VERSION ""

NS_ :

BS_:

BU_: S32V DGPS IPC ADU

BO_ 3221225472 VECTOR__INDEPENDENT_SIG_MSG: 0 Vector__XXX
 SG_ number_of_objects : 0|8@1+ (1,0) [0|64] "" Vector__XXX
 SG_ Obj0_LatitudeDistance : 0|13@1+ (0.01,-40) [-40|41.91] "m" Vector__XXX
 SG_ Obj0_LongitudeDistance : 0|15@1+ (0.01,-100) [-100|227.67] "m" Vector__XXX
 SG_ Obj0_LatitudeSpeed : 0|14@1+ (0.01,-81) [-81|82.83] "m/s" Vector__XXX
 SG_ Obj0_LongitudeSpeed : 0|14@1+ (0.01,-81) [-81|82.83] "m/s" Vector__XXX
 SG_ Obj0_ID : 0|6@1+ (1,0) [1|32] "" Vector__XXX
 SG_ Obj0_Width : 0|10@1+ (0.01,0) [0|10.23] "m" Vector__XXX
 SG_ Obj0_HeadAngle : 0|11@1+ (0.1,-100) [-100|104.7] "deg" Vector__XXX
 SG_ Obj0_type : 0|4@1+ (1,0) [0|15] "m" Vector__XXX
 SG_ Obj0_Length : 0|12@1+ (0.01,0) [0|40.95] "m" Vector__XXX
 SG_ Obj1_LatitudeDistance : 0|13@1+ (0.01,-40) [-40|41.91] "m" Vector__XXX
 SG_ Obj1_LongitudeDistance : 0|15@1+ (0.01,-100) [-100|227.67] "m" Vector__XXX
 SG_ Obj1_LatitudeSpeed : 0|14@1+ (0.01,-81) [-81|82.83] "m/s" Vector__XXX
 SG_ Obj1_LongitudeSpeed : 0|14@1+ (0.01,-81) [-81|82.83] "m/s" Vector__XXX
 SG_ Obj1_ID : 0|6@1+ (1,0) [1|32] "" Vector__XXX
 SG_ Obj1_Width : 0|10@1+ (0.01,0) [0|10.23] "m" Vector__XXX
 SG_ Obj1_HeadAngle : 0|11@1+ (0.1,-100) [-100|104.7] "deg" Vector__XXX
 SG_ Obj1_type : 0|4@1+ (1,0) [0|15] "m" Vector__XXX
 SG_ Obj1_Length : 0|12@1+ (0.01,0) [0|40.95] "m" Vector__XXX
 SG_ Obj2_LatitudeDistance : 0|13@1+ (0.01,-40) [-40|41.91] "m" Vector__XXX
 SG_ Obj2_LongitudeDistance : 0|15@1+ (0.01,-100) [-100|227.67] "m" Vector__XXX
 SG_ Obj2_LatitudeSpeed : 0|14@1+ (0.01,-81) [-81|82.83] "m/s" Vector__XXX
 SG_ Obj2_LongitudeSpeed : 0|14@1+ (0.01,-81) [-81|82.83] "m/s" Vector__XXX
 SG_ Obj2_ID : 0|6@1+ (1,0) [1|32] "" Vector__XXX
 SG_ Obj2_Width : 0|10@1+ (0.01,0) [0|10.23] "m" Vector__XXX
 SG_ Obj2_HeadAngle : 0|11@1+ (0.1,-100) [-100|104.7] "deg" Vector__XXX
 SG_ Obj2_type : 0|4@1+ (1,0) [0|15] "m" Vector__XXX
 SG_ Obj2_Length : 0|12@1+ (0.01,0) [0|40.95] "m" Vector__XXX
 SG_ Obj3_LatitudeDistance : 0|13@1+ (0.01,-40) [-40|41.91] "m" Vector__XXX
 SG_ Obj3_LongitudeDistance : 0|15@1+ (0.01,-100) [-100|227.67] "m" Vector__XXX
 SG_ Obj3_LatitudeSpeed : 0|14@1+ (0.01,-81) [-81|82.83] "m/s" Vector__XXX
 SG_ Obj3_LongitudeSpeed : 0|14@1+ (0.01,-81) [-81|82.83] "m/s" Vector__XXX
 SG_ Obj3_ID : 0|6@1+ (1,0) [1|32] "" Vector__XXX
 SG_ Obj3_Width : 0|10@1+ (0.01,0) [0|10.23] "m" Vector__XXX
 SG_ Obj3_HeadAngle : 0|11@1+ (0.1,-100) [-100|104.7] "deg" Vector__XXX
 SG_ Obj3_type : 0|4@1+ (1,0) [0|15] "m" Vector__XXX
 SG_ Obj3_Length : 0|12@1+ (0.01,0) [0|40.95] "m" Vector__XXX
 SG_ Obj4_LatitudeDistance : 0|13@1+ (0.01,-40) [-40|41.91] "m" Vector__XXX
 SG_ Obj4_LongitudeDistance : 0|15@1+ (0.01,-100) [-100|227.67] "m" Vector__XXX
 SG_ Obj4_LatitudeSpeed : 0|14@1+ (0.01,-81) [-81|82.83] "m/s" Vector__XXX
 SG_ Obj4_LongitudeSpeed : 0|14@1+ (0.01,-81) [-81|82.83] "m/s" Vector__XXX
 SG_ Obj4_ID : 0|6@1+ (1,0) [1|32] "" Vector__XXX
 SG_ Obj4_Width : 0|10@1+ (0.01,0) [0|10.23] "m" Vector__XXX
 SG_ Obj4_HeadAngle : 0|11@1+ (0.1,-100) [-100|104.7] "deg" Vector__XXX
 SG_ Obj4_type : 0|4@1+ (1,0) [0|15] "m" Vector__XXX
 SG_ Obj4_Length : 0|12@1+ (0.01,0) [0|40.95] "m" Vector__XXX
 SG_ Obj5_LatitudeDistance : 0|13@1+ (0.01,-40) [-40|41.91] "m" Vector__XXX
 SG_ Obj5_LongitudeDistance : 0|15@1+ (0.01,-100) [-100|227.67] "m" Vector__XXX
 SG_ Obj5_LatitudeSpeed : 0|14@1+ (0.01,-81) [-81|82.83] "m/s" Vector__XXX
 SG_ Obj5_LongitudeSpeed : 0|14@1+ (0.01,-81) [-81|82.83] "m/s" Vector__XXX
 SG_ Obj5_ID : 0|6@1+ (1,0) [1|32] "" Vector__XXX
 SG_ Obj5_Width : 0|10@1+ (0.01,0) [0|10.23] "m" Vector__XXX
 SG_ Obj5_HeadAngle : 0|11@1+ (0.1,-100) [-100|104.7] "deg" Vector__XXX
 SG_ Obj5_type : 0|4@1+ (1,0) [0|15] "m" Vector__XXX
 SG_ Obj5_Length : 0|12@1+ (0.01,0) [0|40.95] "m" Vector__XXX
 SG_ Obj6_LatitudeDistance : 0|13@1+ (0.01,-40) [-40|41.91] "m" Vector__XXX
 SG_ Obj6_LongitudeDistance : 0|15@1+ (0.01,-100) [-100|227.67] "m" Vector__XXX
 SG_ Obj6_LatitudeSpeed : 0|14@1+ (0.01,-81) [-81|82.83] "m/s" Vector__XXX
 SG_ Obj6_LongitudeSpeed : 0|14@1+ (0.01,-81) [-81|82.83] "m/s" Vector__XXX
 SG_ Obj6_ID : 0|6@1+ (1,0) [1|32] "" Vector__XXX
 SG_ Obj6_Width : 0|10@1+ (0.01,0) [0|10.23] "m" Vector__XXX
 SG_ Obj6_HeadAngle : 0|11@1+ (0.1,-100) [-100|104.7] "deg" Vector__XXX
 SG_ Obj6_type : 0|4@1+ (1,0) [0|15] "m" Vector__XXX
 SG_ Obj6_Length : 0|12@1+ (0.01,0) [0|40.95] "m" Vector__XXX
 SG_ Obj7_LatitudeDistance : 0|13@1+ (0.01,-40) [-40|41.91] "m" Vector__XXX
 SG_ Obj7_LongitudeDistance : 0|15@1+ (0.01,-100) [-100|227.67] "m" Vector__XXX
 SG_ Obj7_LatitudeSpeed : 0|14@1+ (0.01,-81) [-81|82.83] "m/s" Vector__XXX
 SG_ Obj7_LongitudeSpeed : 0|14@1+ (0.01,-81) [-81|82.83] "m/s" Vector__XXX
 SG_ Obj7_ID : 0|6@1+ (1,0) [1|32] "" Vector__XXX
 SG_ Obj7_Width : 0|10@1+ (0.01,0) [0|10.23] "m" Vector__XXX
 SG_ Obj7_HeadAngle : 0|11@1+ (0.1,-100) [-100|104.7] "deg" Vector__XXX
 SG_ Obj7_type : 0|4@1+ (1,0) [0|15] "m" Vector__XXX
 SG_ Obj7_Length : 0|12@1+ (0.01,0) [0|40.95] "m" Vector__XXX
 SG_ Obj8_LatitudeDistance : 0|13@1+ (0.01,-40) [-40|41.91] "m" Vector__XXX
 SG_ Obj8_LongitudeDistance : 0|15@1+ (0.01,-100) [-100|227.67] "m" Vector__XXX
 SG_ Obj8_LatitudeSpeed : 0|14@1+ (0.01,-81) [-81|82.83] "m/s" Vector__XXX
 SG_ Obj8_LongitudeSpeed : 0|14@1+ (0.01,-81) [-81|82.83] "m/s" Vector__XXX
 SG_ Obj8_ID : 0|6@1+ (1,0) [1|32] "" Vector__XXX
 SG_ Obj8_Width : 0|10@1+ (0.01,0) [0|10.23] "m" Vector__XXX
 SG_ Obj8_HeadAngle : 0|11@1+ (0.1,-100) [-100|104.7] "deg" Vector__XXX
 SG_ Obj8_type : 0|4@1+ (1,0) [0|15] "m" Vector__XXX
 SG_ Obj8_Length : 0|12@1+ (0.01,0) [0|40.95] "m" Vector__XXX
 SG_ Obj9_LatitudeDistance : 0|13@1+ (0.01,-40) [-40|41.91] "m" Vector__XXX
 SG_ Obj9_LongitudeDistance : 0|15@1+ (0.01,-100) [-100|227.67] "m" Vector__XXX
 SG_ Obj9_LatitudeSpeed : 0|14@1+ (0.01,-81) [-81|82.83] "m/s" Vector__XXX
 SG_ Obj9_LongitudeSpeed : 0|14@1+ (0.01,-81) [-81|82.83] "m/s" Vector__XXX
 SG_ Obj9_ID : 0|6@1+ (1,0) [1|32] "" Vector__XXX
 SG_ Obj9_Width : 0|10@1+ (0.01,0) [0|10.23] "m" Vector__XXX
 SG_ Obj9_HeadAngle : 0|11@1+ (0.1,-100) [-100|104.7] "deg" Vector__XXX
 SG_ Obj9_type : 0|4@1+ (1,0) [0|15] "m" Vector__XXX
 SG_ Obj9_Length : 0|12@1+ (0.01,0) [0|40.95] "m" Vector__XXX
 SG_ Obj10_LatitudeDistance : 0|13@1+ (0.01,-40) [-40|41.91] "m" Vector__XXX
 SG_ Obj10_LongitudeDistance : 0|15@1+ (0.01,-100) [-100|227.67] "m" Vector__XXX
 SG_ Obj10_LatitudeSpeed : 0|14@1+ (0.01,-81) [-81|82.83] "m/s" Vector__XXX
 SG_ Obj10_LongitudeSpeed : 0|14@1+ (0.01,-81) [-81|82.83] "m/s" Vector__XXX
 SG_ Obj10_ID : 0|6@1+ (1,0) [1|32] "" Vector__XXX
 SG_ Obj10_Width : 0|10@1+ (0.01,0) [0|10.23] "m" Vector__XXX
 SG_ Obj10_HeadAngle : 0|11@1+ (0.1,-100) [-100|104.7] "deg" Vector__XXX
 SG_ Obj10_type : 0|4@1+ (1,0) [0|15] "m" Vector__XXX
 SG_ Obj10_Length : 0|12@1+ (0.01,0) [0|40.95] "m" Vector__XXX
 SG_ Obj11_LatitudeDistance : 0|13@1+ (0.01,-40) [-40|41.91] "m" Vector__XXX
 SG_ Obj11_LongitudeDistance : 0|15@1+ (0.01,-100) [-100|227.67] "m" Vector__XXX
 SG_ Obj11_LatitudeSpeed : 0|14@1+ (0.01,-81) [-81|82.83] "m/s" Vector__XXX
 SG_ Obj11_LongitudeSpeed : 0|14@1+ (0.01,-81) [-81|82.83] "m/s" Vector__XXX
 SG_ Obj11_ID : 0|6@1+ (1,0) [1|32] "" Vector__XXX
 SG_ Obj11_Width : 0|10@1+ (0.01,0) [0|10.23] "m" Vector__XXX
 SG_ Obj11_HeadAngle : 0|11@1+ (0.1,-100) [-100|104.7] "deg" Vector__XXX
 SG_ Obj11_type : 0|4@1+ (1,0) [0|15] "m" Vector__XXX
 SG_ Obj11_Length : 0|12@1+ (0.01,0) [0|40.95] "m" Vector__XXX
 SG_ Obj12_LatitudeDistance : 0|13@1+ (0.01,-40) [-40|41.91] "m" Vector__XXX
 SG_ Obj12_LongitudeDistance : 0|15@1+ (0.01,-100) [-100|227.67] "m" Vector__XXX
 SG_ Obj12_LatitudeSpeed : 0|14@1+ (0.01,-81) [-81|82.83] "m/s" Vector__XXX
 SG_ Obj12_LongitudeSpeed : 0|14@1+ (0.01,-81) [-81|82.83] "m/s" Vector__XXX
 SG_ Obj12_ID : 0|6@1+ (1,0) [1|32] "" Vector__XXX
 SG_ Obj12_Width : 0|10@1+ (0.01,0) [0|10.23] "m" Vector__XXX
 SG_ Obj12_HeadAngle : 0|11@1+ (0.1,-100) [-100|104.7] "deg" Vector__XXX
 SG_ Obj12_type : 0|4@1+ (1,0) [0|15] "m" Vector__XXX
 SG_ Obj12_Length : 0|12@1+ (0.01,0) [0|40.95] "m" Vector__XXX
 SG_ Obj13_LatitudeDistance : 0|13@1+ (0.01,-40) [-40|41.91] "m" Vector__XXX
 SG_ Obj13_LongitudeDistance : 0|15@1+ (0.01,-100) [-100|227.67] "m" Vector__XXX
 SG_ Obj13_LatitudeSpeed : 0|14@1+ (0.01,-81) [-81|82.83] "m/s" Vector__XXX
 SG_ Obj13_LongitudeSpeed : 0|14@1+ (0.01,-81) [-81|82.83] "m/s" Vector__XXX
 SG_ Obj13_ID : 0|6@1+ (1,0) [1|32] "" Vector__XXX
 SG_ Obj13_Width : 0|10@1+ (0.01,0) [0|10.23] "m" Vector__XXX
 SG_ Obj13_HeadAngle : 0|11@1+ (0.1,-100) [-100|104.7] "deg" Vector__XXX
 SG_ Obj13_type : 0|4@1+ (1,0) [0|15] "m" Vector__XXX
 SG_ Obj13_Length : 0|12@1+ (0.01,0) [0|40.95] "m" Vector__XXX
 SG_ Obj14_LatitudeDistance : 0|13@1+ (0.01,-40) [-40|41.91] "m" Vector__XXX
 SG_ Obj14_LongitudeDistance : 0|15@1+ (0.01,-100) [-100|227.67] "m" Vector__XXX
 SG_ Obj14_LatitudeSpeed : 0|14@1+ (0.01,-81) [-81|82.83] "m/s" Vector__XXX
 SG_ Obj14_LongitudeSpeed : 0|14@1+ (0.01,-81) [-81|82.83] "m/s" Vector__XXX
 SG_ Obj14_ID : 0|6@1+ (1,0) [1|32] "" Vector__XXX
 SG_ Obj14_Width : 0|10@1+ (0.01,0) [0|10.23] "m" Vector__XXX
 SG_ Obj14_HeadAngle : 0|11@1+ (0.1,-100) [-100|104.7] "deg" Vector__XXX
 SG_ Obj14_type : 0|4@1+ (1,0) [0|15] "m" Vector__XXX
 SG_ Obj14_Length : 0|12@1+ (0.01,0) [0|40.95] "m" Vector__XXX
 SG_ Obj15_LatitudeDistance : 0|13@1+ (0.01,-40) [-40|41.91] "m" Vector__XXX
 SG_ Obj15_LongitudeDistance : 0|15@1+ (0.01,-100) [-100|227.67] "m" Vector__XXX
 SG_ Obj15_LatitudeSpeed : 0|14@1+ (0.01,-81) [-81|82.83] "m/s" Vector__XXX
 SG_ Obj15_LongitudeSpeed : 0|14@1+ (0.01,-81) [-81|82.83] "m/s" Vector__XXX
 SG_ Obj15_ID : 0|6@1+ (1,0) [1|32] "" Vector__XXX
 SG_ Obj15_Width : 0|10@1+ (0.01,0) [0|10.23] "m" Vector__XXX
 SG_ Obj15_HeadAngle : 0|11@1+ (0.1,-100) [-100|104.7] "deg" Vector__XXX
 SG_ Obj15_type : 0|4@1+ (1,0) [0|15] "m" Vector__XXX
 SG_ Obj15_Length : 0|12@1+ (0.01,0) [0|40.95] "m" Vector__XXX
 SG_ Obj16_LatitudeDistance : 0|13@1+ (0.01,-40) [-40|41.91] "m" Vector__XXX
 SG_ Obj16_LongitudeDistance : 0|15@1+ (0.01,-100) [-100|227.67] "m" Vector__XXX
 SG_ Obj16_LatitudeSpeed : 0|14@1+ (0.01,-81) [-81|82.83] "m/s" Vector__XXX
 SG_ Obj16_LongitudeSpeed : 0|14@1+ (0.01,-81) [-81|82.83] "m/s" Vector__XXX
 SG_ Obj16_ID : 0|6@1+ (1,0) [1|32] "" Vector__XXX
 SG_ Obj16_Width : 0|10@1+ (0.01,0) [0|10.23] "m" Vector__XXX
 SG_ Obj16_HeadAngle : 0|11@1+ (0.1,-100) [-100|104.7] "deg" Vector__XXX
 SG_ Obj16_type : 0|4@1+ (1,0) [0|15] "m" Vector__XXX
 SG_ Obj16_Length : 0|12@1+ (0.01,0) [0|40.95] "m" Vector__XXX
 SG_ Obj17_LatitudeDistance : 0|13@1+ (0.01,-40) [-40|41.91] "m" Vector__XXX
 SG_ Obj17_LongitudeDistance : 0|15@1+ (0.01,-100) [-100|227.67] "m" Vector__XXX
 SG_ Obj17_LatitudeSpeed : 0|14@1+ (0.01,-81) [-81|82.83] "m/s" Vector__XXX
 SG_ Obj17_LongitudeSpeed : 0|14@1+ (0.01,-81) [-81|82.83] "m/s" Vector__XXX
 SG_ Obj17_ID : 0|6@1+ (1,0) [1|32] "" Vector__XXX
 SG_ Obj17_Width : 0|10@1+ (0.01,0) [0|10.23] "m" Vector__XXX
 SG_ Obj17_HeadAngle : 0|11@1+ (0.1,-100) [-100|104.7] "deg" Vector__XXX
 SG_ Obj17_type : 0|4@1+ (1,0) [0|15] "m" Vector__XXX
 SG_ Obj17_Length : 0|12@1+ (0.01,0) [0|40.95] "m" Vector__XXX
 SG_ Obj18_LatitudeDistance : 0|13@1+ (0.01,-40) [-40|41.91] "m" Vector__XXX
 SG_ Obj18_LongitudeDistance : 0|15@1+ (0.01,-100) [-100|227.67] "m" Vector__XXX
 SG_ Obj18_LatitudeSpeed : 0|14@1+ (0.01,-81) [-81|82.83] "m/s" Vector__XXX
 SG_ Obj18_LongitudeSpeed : 0|14@1+ (0.01,-81) [-81|82.83] "m/s" Vector__XXX
 SG_ Obj18_ID : 0|6@1+ (1,0) [1|32] "" Vector__XXX
 SG_ Obj18_Width : 0|10@1+ (0.01,0) [0|10.23] "m" Vector__XXX
 SG_ Obj18_HeadAngle : 0|11@1+ (0.1,-100) [-100|104.7] "deg" Vector__XXX
 SG_ Obj18_type : 0|4@1+ (1,0) [0|15] "m" Vector__XXX
 SG_ Obj18_Length : 0|12@1+ (0.01,0) [0|40.95] "m" Vector__XXX
 SG_ Obj19_LatitudeDistance : 0|13@1+ (0.01,-40) [-40|41.91] "m" Vector__XXX
 SG_ Obj19_LongitudeDistance : 0|15@1+ (0.01,-100) [-100|227.67] "m" Vector__XXX
 SG_ Obj19_LatitudeSpeed : 0|14@1+ (0.01,-81) [-81|82.83] "m/s" Vector__XXX
 SG_ Obj19_LongitudeSpeed : 0|14@1+ (0.01,-81) [-81|82.83] "m/s" Vector__XXX
 SG_ Obj19_ID : 0|6@1+ (1,0) [1|32] "" Vector__XXX
 SG_ Obj19_Width : 0|10@1+ (0.01,0) [0|10.23] "m" Vector__XXX
 SG_ Obj19_HeadAngle : 0|11@1+ (0.1,-100) [-100|104.7] "deg" Vector__XXX
 SG_ Obj19_type : 0|4@1+ (1,0) [0|15] "m" Vector__XXX
 SG_ Obj19_Length : 0|12@1+ (0.01,0) [0|40.95] "m" Vector__XXX
 SG_ Obj20_LatitudeDistance : 0|13@1+ (0.01,-40) [-40|41.91] "m" Vector__XXX
 SG_ Obj20_LongitudeDistance : 0|15@1+ (0.01,-100) [-100|227.67] "m" Vector__XXX
 SG_ Obj20_LatitudeSpeed : 0|14@1+ (0.01,-81) [-81|82.83] "m/s" Vector__XXX
 SG_ Obj20_LongitudeSpeed : 0|14@1+ (0.01,-81) [-81|82.83] "m/s" Vector__XXX
 SG_ Obj20_ID : 0|6@1+ (1,0) [1|32] "" Vector__XXX
 SG_ Obj20_Width : 0|10@1+ (0.01,0) [0|10.23] "m" Vector__XXX
 SG_ Obj20_HeadAngle : 0|11@1+ (0.1,-100) [-100|104.7] "deg" Vector__XXX
 SG_ Obj20_type : 0|4@1+ (1,0) [0|15] "m" Vector__XXX
 SG_ Obj20_Length : 0|12@1+ (0.01,0) [0|40.95] "m" Vector__XXX
 SG_ Obj21_LatitudeDistance : 0|13@1+ (0.01,-40) [-40|41.91] "m" Vector__XXX
 SG_ Obj21_LongitudeDistance : 0|15@1+ (0.01,-100) [-100|227.67] "m" Vector__XXX
 SG_ Obj21_LatitudeSpeed : 0|14@1+ (0.01,-81) [-81|82.83] "m/s" Vector__XXX
 SG_ Obj21_LongitudeSpeed : 0|14@1+ (0.01,-81) [-81|82.83] "m/s" Vector__XXX
 SG_ Obj21_ID : 0|6@1+ (1,0) [1|32] "" Vector__XXX
 SG_ Obj21_Width : 0|10@1+ (0.01,0) [0|10.23] "m" Vector__XXX
 SG_ Obj21_HeadAngle : 0|11@1+ (0.1,-100) [-100|104.7] "deg" Vector__XXX
 SG_ Obj21_type : 0|4@1+ (1,0) [0|15] "m" Vector__XXX
 SG_ Obj21_Length : 0|12@1+ (0.01,0) [0|40.95] "m" Vector__XXX
 SG_ Obj22_LatitudeDistance : 0|13@1+ (0.01,-40) [-40|41.91] "m" Vector__XXX
 SG_ Obj22_LongitudeDistance : 0|15@1+ (0.01,-100) [-100|227.67] "m" Vector__XXX
 SG_ Obj22_LatitudeSpeed : 0|14@1+ (0.01,-81) [-81|82.83] "m/s" Vector__XXX
 SG_ Obj22_LongitudeSpeed : 0|14@1+ (0.01,-81) [-81|82.83] "m/s" Vector__XXX
 SG_ Obj22_ID : 0|6@1+ (1,0) [1|32] "" Vector__XXX
 SG_ Obj22_Width : 0|10@1+ (0.01,0) [0|10.23] "m" Vector__XXX
 SG_ Obj22_HeadAngle : 0|11@1+ (0.1,-100) [-100|104.7] "deg" Vector__XXX
 SG_ Obj22_type : 0|4@1+ (1,0) [0|15] "m" Vector__XXX
 SG_ Obj22_Length : 0|12@1+ (0.01,0) [0|40.95] "m" Vector__XXX
 SG_ Obj23_LatitudeDistance : 0|13@1+ (0.01,-40) [-40|41.91] "m" Vector__XXX
 SG_ Obj23_LongitudeDistance : 0|15@1+ (0.01,-100) [-100|227.67] "m" Vector__XXX
 SG_ Obj23_LatitudeSpeed : 0|14@1+ (0.01,-81) [-81|82.83] "m/s" Vector__XXX
 SG_ Obj23_LongitudeSpeed : 0|14@1+ (0.01,-81) [-81|82.83] "m/s" Vector__XXX
 SG_ Obj23_ID : 0|6@1+ (1,0) [1|32] "" Vector__XXX
 SG_ Obj23_Width : 0|10@1+ (0.01,0) [0|10.23] "m" Vector__XXX
 SG_ Obj23_HeadAngle : 0|11@1+ (0.1,-100) [-100|104.7] "deg" Vector__XXX
 SG_ Obj23_type : 0|4@1+ (1,0) [0|15] "m" Vector__XXX
 SG_ Obj23_Length : 0|12@1+ (0.01,0) [0|40.95] "m" Vector__XXX
 SG_ Obj24_LatitudeDistance : 0|13@1+ (0.01,-40) [-40|41.91] "m" Vector__XXX
 SG_ Obj24_LongitudeDistance : 0|15@1+ (0.01,-100) [-100|227.67] "m" Vector__XXX
 SG_ Obj24_LatitudeSpeed : 0|14@1+ (0.01,-81) [-81|82.83] "m/s" Vector__XXX
 SG_ Obj24_LongitudeSpeed : 0|14@1+ (0.01,-81) [-81|82.83] "m/s" Vector__XXX
 SG_ Obj24_ID : 0|6@1+ (1,0) [1|32] "" Vector__XXX
 SG_ Obj24_Width : 0|10@1+ (0.01,0) [0|10.23] "m" Vector__XXX
 SG_ Obj24_HeadAngle : 0|11@1+ (0.1,-100) [-100|104.7] "deg" Vector__XXX
 SG_ Obj24_type : 0|4@1+ (1,0) [0|15] "m" Vector__XXX
 SG_ Obj24_Length : 0|12@1+ (0.01,0) [0|40.95] "m" Vector__XXX
 SG_ Obj25_LatitudeDistance : 0|13@1+ (0.01,-40) [-40|41.91] "m" Vector__XXX
 SG_ Obj25_LongitudeDistance : 0|15@1+ (0.01,-100) [-100|227.67] "m" Vector__XXX
 SG_ Obj25_LatitudeSpeed : 0|14@1+ (0.01,-81) [-81|82.83] "m/s" Vector__XXX
 SG_ Obj25_LongitudeSpeed : 0|14@1+ (0.01,-81) [-81|82.83] "m/s" Vector__XXX
 SG_ Obj25_ID : 0|6@1+ (1,0) [1|32] "" Vector__XXX
 SG_ Obj25_Width : 0|10@1+ (0.01,0) [0|10.23] "m" Vector__XXX
 SG_ Obj25_HeadAngle : 0|11@1+ (0.1,-100) [-100|104.7] "deg" Vector__XXX
 SG_ Obj25_type : 0|4@1+ (1,0) [0|15] "m" Vector__XXX
 SG_ Obj25_Length : 0|12@1+ (0.01,0) [0|40.95] "m" Vector__XXX
 SG_ Obj26_LatitudeDistance : 0|13@1+ (0.01,-40) [-40|41.91] "m" Vector__XXX
 SG_ Obj26_LongitudeDistance : 0|15@1+ (0.01,-100) [-100|227.67] "m" Vector__XXX
 SG_ Obj26_LatitudeSpeed : 0|14@1+ (0.01,-81) [-81|82.83] "m/s" Vector__XXX
 SG_ Obj26_LongitudeSpeed : 0|14@1+ (0.01,-81) [-81|82.83] "m/s" Vector__XXX
 SG_ Obj26_ID : 0|6@1+ (1,0) [1|32] "" Vector__XXX
 SG_ Obj26_Width : 0|10@1+ (0.01,0) [0|10.23] "m" Vector__XXX
 SG_ Obj26_HeadAngle : 0|11@1+ (0.1,-100) [-100|104.7] "deg" Vector__XXX
 SG_ Obj26_type : 0|4@1+ (1,0) [0|15] "m" Vector__XXX
 SG_ Obj26_Length : 0|12@1+ (0.01,0) [0|40.95] "m" Vector__XXX
 SG_ Obj27_LatitudeDistance : 0|13@1+ (0.01,-40) [-40|41.91] "m" Vector__XXX
 SG_ Obj27_LongitudeDistance : 0|15@1+ (0.01,-100) [-100|227.67] "m" Vector__XXX
 SG_ Obj27_LatitudeSpeed : 0|14@1+ (0.01,-81) [-81|82.83] "m/s" Vector__XXX
 SG_ Obj27_LongitudeSpeed : 0|14@1+ (0.01,-81) [-81|82.83] "m/s" Vector__XXX
 SG_ Obj27_ID : 0|6@1+ (1,0) [1|32] "" Vector__XXX
 SG_ Obj27_Width : 0|10@1+ (0.01,0) [0|10.23] "m" Vector__XXX
 SG_ Obj27_HeadAngle : 0|11@1+ (0.1,-100) [-100|104.7] "deg" Vector__XXX
 SG_ Obj27_type : 0|4@1+ (1,0) [0|15] "m" Vector__XXX
 SG_ Obj27_Length : 0|12@1+ (0.01,0) [0|40.95] "m" Vector__XXX
 SG_ Obj28_LatitudeDistance : 0|13@1+ (0.01,-40) [-40|41.91] "m" Vector__XXX
 SG_ Obj28_LongitudeDistance : 0|15@1+ (0.01,-100) [-100|227.67] "m" Vector__XXX
 SG_ Obj28_LatitudeSpeed : 0|14@1+ (0.01,-81) [-81|82.83] "m/s" Vector__XXX
 SG_ Obj28_LongitudeSpeed : 0|14@1+ (0.01,-81) [-81|82.83] "m/s" Vector__XXX
 SG_ Obj28_ID : 0|6@1+ (1,0) [1|32] "" Vector__XXX
 SG_ Obj28_Width : 0|10@1+ (0.01,0) [0|10.23] "m" Vector__XXX
 SG_ Obj28_HeadAngle : 0|11@1+ (0.1,-100) [-100|104.7] "deg" Vector__XXX
 SG_ Obj28_type : 0|4@1+ (1,0) [0|15] "m" Vector__XXX
 SG_ Obj28_Length : 0|12@1+ (0.01,0) [0|40.95] "m" Vector__XXX
 SG_ Obj29_LatitudeDistance : 0|13@1+ (0.01,-40) [-40|41.91] "m" Vector__XXX
 SG_ Obj29_LongitudeDistance : 0|15@1+ (0.01,-100) [-100|227.67] "m" Vector__XXX
 SG_ Obj29_LatitudeSpeed : 0|14@1+ (0.01,-81) [-81|82.83] "m/s" Vector__XXX
 SG_ Obj29_LongitudeSpeed : 0|14@1+ (0.01,-81) [-81|82.83] "m/s" Vector__XXX
 SG_ Obj29_ID : 0|6@1+ (1,0) [1|32] "" Vector__XXX
 SG_ Obj29_Width : 0|10@1+ (0.01,0) [0|10.23] "m" Vector__XXX
 SG_ Obj29_HeadAngle : 0|11@1+ (0.1,-100) [-100|104.7] "deg" Vector__XXX
 SG_ Obj29_type : 0|4@1+ (1,0) [0|15] "m" Vector__XXX
 SG_ Obj29_Length : 0|12@1+ (0.01,0) [0|40.95] "m" Vector__XXX
 SG_ Obj30_LatitudeDistance : 0|13@1+ (0.01,-40) [-40|41.91] "m" Vector__XXX
 SG_ Obj30_LongitudeDistance : 0|15@1+ (0.01,-100) [-100|227.67] "m" Vector__XXX
 SG_ Obj30_LatitudeSpeed : 0|14@1+ (0.01,-81) [-81|82.83] "m/s" Vector__XXX
 SG_ Obj30_LongitudeSpeed : 0|14@1+ (0.01,-81) [-81|82.83] "m/s" Vector__XXX
 SG_ Obj30_ID : 0|6@1+ (1,0) [1|32] "" Vector__XXX
 SG_ Obj30_Width : 0|10@1+ (0.01,0) [0|10.23] "m" Vector__XXX
 SG_ Obj30_HeadAngle : 0|11@1+ (0.1,-100) [-100|104.7] "deg" Vector__XXX
 SG_ Obj30_type : 0|4@1+ (1,0) [0|15] "m" Vector__XXX
 SG_ Obj30_Length : 0|12@1+ (0.01,0) [0|40.95] "m" Vector__XXX
 SG_ Obj31_LatitudeDistance : 0|13@1+ (0.01,-40) [-40|41.91] "m" Vector__XXX
 SG_ Obj31_LongitudeDistance : 0|15@1+ (0.01,-100) [-100|227.67] "m" Vector__XXX
 SG_ Obj31_LatitudeSpeed : 0|14@1+ (0.01,-81) [-81|82.83] "m/s" Vector__XXX
 SG_ Obj31_LongitudeSpeed : 0|14@1+ (0.01,-81) [-81|82.83] "m/s" Vector__XXX
 SG_ Obj31_ID : 0|6@1+ (1,0) [1|32] "" Vector__XXX
 SG_ Obj31_Width : 0|10@1+ (0.01,0) [0|10.23] "m" Vector__XXX
 SG_ Obj31_HeadAngle : 0|11@1+ (0.1,-100) [-100|104.7] "deg" Vector__XXX
 SG_ Obj31_type : 0|4@1+ (1,0) [0|15] "m" Vector__XXX
 SG_ Obj31_Length : 0|12@1+ (0.01,0) [0|40.95] "m" Vector__XXX
 SG_ GPS_PDOP : 0|16@0+ (0.001,0) [0|65.535] "" Vector__XXX
 SG_ GPS_HDOP : 0|16@0+ (0.001,0) [0|65.535] "" Vector__XXX
 SG_ GPS_VDOP : 0|16@0+ (0.001,0) [0|65.535] "" Vector__XXX
 SG_ GPS_GDOP : 0|16@0+ (0.001,0) [0|65.535] "" Vector__XXX
 SG_ GPS_HeadingAngle : 0|32@0+ (1E-007,-180) [-180|180] "deg" Vector__XXX
 SG_ GPS_LocatHeight : 0|32@0+ (0.001,-10000) [-10000|4284967.295] "m" Vector__XXX
 SG_ GPS_Time : 0|32@0+ (1,0) [0|4294967295] "ms" Vector__XXX
 SG_ GPS_Latitude : 0|32@0+ (1E-007,-180) [-180|180] "deg" Vector__XXX
 SG_ GPS_Lontitude : 0|32@0+ (1E-007,-90) [-90|339.4967295] "deg" Vector__XXX
 SG_ GPS_UTC_sec : 0|32@0+ (1,0) [0|4294967295] "" Vector__XXX
 SG_ GPS_UTC_week : 0|16@0+ (1,0) [0|65500] "" Vector__XXX
 SG_ INS_A_Y : 0|16@0+ (0.00012207,-4) [-4|3.99985745] "m/s^2" Vector__XXX
 SG_ INS_A_X : 0|16@0+ (0.00012207,-4) [-4|3.99985745] "m/s^2" Vector__XXX
 SG_ INS_A_Z : 0|16@0+ (0.00012207,-4) [-4|3.99985745] "m/s^2" Vector__XXX
 SG_ GPS_flag_pos : 0|8@0+ (1,0) [0|60] "" Vector__XXX
 SG_ GPS_flag_heading : 0|8@0+ (1,0) [0|255] "" Vector__XXX
 SG_ GPS_age : 0|8@0+ (1,0) [0|100] "" Vector__XXX
 SG_ car_statue : 0|8@0+ (1,0) [0|12] "" Vector__XXX
 SG_ INS_statue : 0|8@0+ (1,0) [0|255] "" Vector__XXX
 SG_ GPS_numsv : 0|8@0+ (1,0) [0|255] "" Vector__XXX
 SG_ INS_GYRO_Y : 0|16@0+ (0.0076293,-250) [-250|249.9861755] "deg/s" Vector__XXX
 SG_ INS_GYRO_Z : 0|16@0+ (0.0076293,-250) [-250|249.9861755] "deg/s" Vector__XXX
 SG_ INS_GYRO_X : 0|16@0+ (0.0076293,-250) [-250|249.9861755] "deg/s" Vector__XXX
 SG_ INS_RollAngle : 0|16@0+ (0.010986,-360) [-360|359.96751] "deg" Vector__XXX
 SG_ INS_HeadingAngle : 0|16@0+ (0.010986,-360) [-360|359.96751] "deg" Vector__XXX
 SG_ INS_PitchAngle : 0|16@0+ (0.010986,-360) [-360|359.96751] "deg" Vector__XXX
 SG_ INS_LocatHeight : 0|32@0+ (0.001,-10000) [-10000|4284967.295] "m" Vector__XXX
 SG_ INS_Time : 0|32@0+ (1,0) [0|4294967295] "ms" Vector__XXX
 SG_ INS_Latitude : 0|32@0+ (1E-007,-180) [-180|180] "deg" Vector__XXX
 SG_ INS_Longitude : 0|32@0+ (1E-007,-180) [-180|180] "deg" Vector__XXX
 SG_ INS_NorthSpd : 0|16@0+ (0.0030517,-100) [-100|99.9901078] "m/s" Vector__XXX
 SG_ INS_ToGroundSpd : 0|16@0+ (0.0030517,-100) [-100|99.9901078] "m/s" Vector__XXX
 SG_ INS_EastSpd : 0|16@0+ (0.0030517,-100) [-100|99.9901078] "m/s" Vector__XXX
 SG_ INS_Std_Lon : 0|16@0+ (0.001,0) [0|65.535] "m" Vector__XXX
 SG_ INS_Std_Height : 0|16@0+ (0.001,0) [0|65.535] "m" Vector__XXX
 SG_ INS_Std_Lat : 0|16@0+ (0.001,0) [0|65.535] "m" Vector__XXX
 SG_ IPC_CPSLaneNumber : 0|4@1+ (1,0) [0|15] "" Vector__XXX
 SG_ IPC_CPSDirectionIndication : 0|2@1+ (1,0) [0|3] "" Vector__XXX
 SG_ IPC_CPSCameraUsed : 0|2@1+ (1,0) [0|3] "" Vector__XXX
 SG_ IPC_BayNumberCameraUsed : 0|2@1+ (1,0) [0|3] "" Vector__XXX
 SG_ IPC_BayNumber : 0|8@1+ (1,0) [0|99] "" Vector__XXX
 SG_ IPC_BayRemainingDistanceX : 0|16@1+ (1,-3000) [-3000|3000] "" Vector__XXX
 SG_ IPC_BayRemainingDistanceY : 0|16@1+ (1,-3000) [-3000|3000] "" Vector__XXX
 SG_ IPC_CPSDisplayNumber : 0|8@1+ (1,0) [0|99] "cm" Vector__XXX
 SG_ IPC_ContainerSizeAndPosition : 0|4@1+ (1,0) [0|15] "" Vector__XXX
 SG_ IPC_CPSRightCameraStatus : 0|5@1+ (1,0) [0|31] "" Vector__XXX
 SG_ IPC_BayNumLeftCameraStatus : 0|5@1+ (1,0) [0|31] "" Vector__XXX
 SG_ IPC_BayNumRightCameraStatus : 0|5@1+ (1,0) [0|31] "" Vector__XXX
 SG_ IPC_HangerCameraStatus : 0|5@1+ (1,0) [0|31] "" Vector__XXX
 SG_ IPC_HangerStatus : 0|4@1+ (1,0) [0|15] "" Vector__XXX
 SG_ IPC_CPSLeftCameraStatus : 0|5@1+ (1,0) [0|31] "" Vector__XXX
 SG_ S32V_ToADU_Reserved1 : 0|16@1+ (1,0) [0|65535] "" Vector__XXX
 SG_ S32V_ToADU_Reserved2 : 0|16@1+ (1,0) [0|65535] "" Vector__XXX
 SG_ S32V_ToADU_Reserved3 : 0|16@1+ (1,0) [0|65535] "" Vector__XXX
 SG_ S32V_ToADU_Reserved4 : 0|16@1+ (1,0) [0|65535] "" Vector__XXX
 SG_ S32V_ToADU_Reserved5 : 0|16@1+ (1,0) [0|65535] "" Vector__XXX
 SG_ S32V_ToADU_Reserved6 : 0|16@1+ (1,0) [0|65535] "" Vector__XXX
 SG_ S32V_ToADU_Reserved7 : 0|16@1+ (1,0) [0|65535] "" Vector__XXX
 SG_ S32V_ToADU_Reserved8 : 0|16@1+ (1,0) [0|65535] "" Vector__XXX
 SG_ S32V_ToADU_Reserved9 : 0|16@1+ (1,0) [0|65535] "" Vector__XXX
 SG_ S32V_ToADU_Reserved10 : 0|16@1+ (1,0) [0|65535] "" Vector__XXX
 SG_ S32V_ToADU_Reserved11 : 0|16@1+ (1,0) [0|65535] "" Vector__XXX
 SG_ S32V_ToADU_Reserved12 : 0|16@1+ (1,0) [0|65535] "" Vector__XXX
 SG_ S32V_ToADU_Reserved13 : 0|8@1+ (1,0) [0|255] "" Vector__XXX
 SG_ S32V_ToADU_Reserved15 : 0|8@1+ (1,0) [0|255] "" Vector__XXX
 SG_ S32V_ToADU_Reserved16 : 0|8@1+ (1,0) [0|255] "" Vector__XXX
 SG_ S32V_ToADU_Reserved17 : 0|8@1+ (1,0) [0|255] "" Vector__XXX
 SG_ S32V_ToADU_Reserved18 : 0|8@1+ (1,0) [0|255] "" Vector__XXX
 SG_ S32V_ToADU_Reserved19 : 0|8@1+ (1,0) [0|255] "" Vector__XXX
 SG_ S32V_ToADU_Reserved20 : 0|8@1+ (1,0) [0|255] "" Vector__XXX
 SG_ S32V_ToADU_Reserved14 : 0|8@1+ (1,0) [0|255] "" Vector__XXX
 SG_ S32V_ToADU_Reserved21 : 0|8@1+ (1,0) [0|255] "" Vector__XXX
 SG_ S32V_ToADU_Reserved23 : 0|8@1+ (1,0) [0|255] "" Vector__XXX
 SG_ S32V_ToADU_Reserved24 : 0|8@1+ (1,0) [0|255] "" Vector__XXX
 SG_ S32V_ToADU_Reserved25 : 0|8@1+ (1,0) [0|255] "" Vector__XXX
 SG_ S32V_ToADU_Reserved26 : 0|8@1+ (1,0) [0|255] "" Vector__XXX
 SG_ S32V_ToADU_Reserved27 : 0|8@1+ (1,0) [0|255] "" Vector__XXX
 SG_ S32V_ToADU_Reserved28 : 0|8@1+ (1,0) [0|255] "" Vector__XXX
 SG_ S32V_ToADU_Reserved22 : 0|8@1+ (1,0) [0|255] "" Vector__XXX
 SG_ adu_ToS32V_Reserved1 : 0|16@1+ (1,0) [0|65535] "" Vector__XXX
 SG_ adu_ToS32V_Reserved2 : 0|16@1+ (1,0) [0|65535] "" Vector__XXX
 SG_ adu_ToS32V_Reserved3 : 0|16@1+ (1,0) [0|65535] "" Vector__XXX
 SG_ adu_ToS32V_Reserved4 : 0|16@1+ (1,0) [0|65535] "" Vector__XXX
 SG_ adu_ToS32V_Reserved5 : 0|16@1+ (1,0) [0|65535] "" Vector__XXX
 SG_ adu_ToS32V_Reserved6 : 0|16@1+ (1,0) [0|65535] "" Vector__XXX
 SG_ adu_ToS32V_Reserved7 : 0|16@1+ (1,0) [0|65535] "" Vector__XXX
 SG_ adu_ToS32V_Reserved8 : 0|16@1+ (1,0) [0|65535] "" Vector__XXX
 SG_ adu_ToS32V_Reserved9 : 0|16@1+ (1,0) [0|65535] "" Vector__XXX
 SG_ adu_ToS32V_Reserved10 : 0|16@1+ (1,0) [0|65535] "" Vector__XXX
 SG_ adu_ToS32V_Reserved11 : 0|16@1+ (1,0) [0|65535] "" Vector__XXX
 SG_ adu_ToS32V_Reserved12 : 0|16@1+ (1,0) [0|65535] "" Vector__XXX
 SG_ adu_ToS32V_Reserved13 : 0|8@1+ (1,0) [0|255] "" Vector__XXX
 SG_ adu_ToS32V_Reserved15 : 0|8@1+ (1,0) [0|255] "" Vector__XXX
 SG_ adu_ToS32V_Reserved16 : 0|8@1+ (1,0) [0|255] "" Vector__XXX
 SG_ adu_ToS32V_Reserved17 : 0|8@1+ (1,0) [0|255] "" Vector__XXX
 SG_ adu_ToS32V_Reserved18 : 0|8@1+ (1,0) [0|255] "" Vector__XXX
 SG_ adu_ToS32V_Reserved19 : 0|8@1+ (1,0) [0|255] "" Vector__XXX
 SG_ adu_ToS32V_Reserved20 : 0|8@1+ (1,0) [0|255] "" Vector__XXX
 SG_ adu_ToS32V_Reserved14 : 0|8@1+ (1,0) [0|255] "" Vector__XXX
 SG_ adu_ToS32V_Reserved21 : 0|8@1+ (1,0) [0|255] "" Vector__XXX
 SG_ adu_ToS32V_Reserved23 : 0|8@1+ (1,0) [0|255] "" Vector__XXX
 SG_ adu_ToS32V_Reserved24 : 0|8@1+ (1,0) [0|255] "" Vector__XXX
 SG_ adu_ToS32V_Reserved25 : 0|8@1+ (1,0) [0|255] "" Vector__XXX
 SG_ adu_ToS32V_Reserved26 : 0|8@1+ (1,0) [0|255] "" Vector__XXX
 SG_ adu_ToS32V_Reserved27 : 0|8@1+ (1,0) [0|255] "" Vector__XXX
 SG_ adu_ToS32V_Reserved28 : 0|8@1+ (1,0) [0|255] "" Vector__XXX
 SG_ adu_ToS32V_Reserved22 : 0|8@1+ (1,0) [0|255] "" Vector__XXX

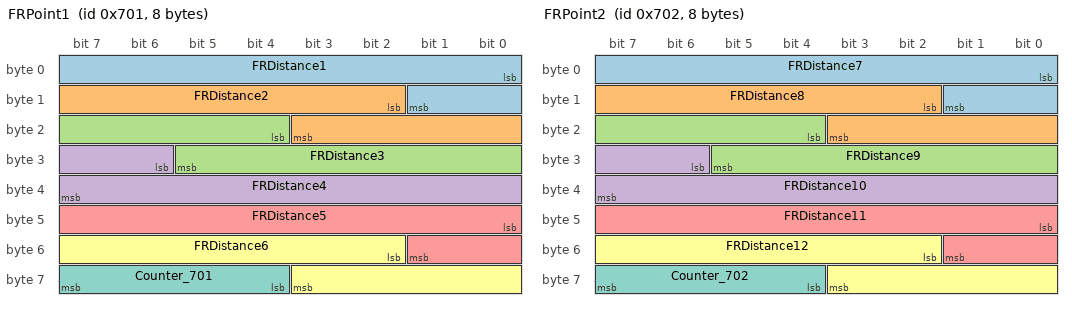
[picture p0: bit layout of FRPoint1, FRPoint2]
BO_ 1793 FRPoint1: 8 S32V
 SG_ FRDistance1 : 0|10@1+ (0.1,0) [0|102.3] "m"  ADU
 SG_ FRDistance2 : 10|10@1+ (0.1,0) [0|102.3] "m"  ADU
 SG_ FRDistance3 : 20|10@1+ (0.1,0) [0|102.3] "m"  ADU
 SG_ FRDistance4 : 30|10@1+ (0.1,0) [0|102.3] "m"  ADU
 SG_ FRDistance5 : 40|10@1+ (0.1,0) [0|102.3] "m"  ADU
 SG_ FRDistance6 : 50|10@1+ (0.1,0) [0|102.3] "m"  ADU
 SG_ Counter_701 : 60|4@1+ (1,0) [0|15] ""  ADU

BO_ 1794 FRPoint2: 8 S32V
 SG_ FRDistance7 : 0|10@1+ (0.1,0) [0|102.3] "m"  ADU
 SG_ FRDistance8 : 10|10@1+ (0.1,0) [0|102.3] "m"  ADU
 SG_ FRDistance9 : 20|10@1+ (0.1,0) [0|102.3] "m"  ADU
 SG_ FRDistance10 : 30|10@1+ (0.1,0) [0|102.3] "m"  ADU
 SG_ FRDistance11 : 40|10@1+ (0.1,0) [0|102.3] "m"  ADU
 SG_ FRDistance12 : 50|10@1+ (0.1,0) [0|102.3] "m"  ADU
 SG_ Counter_702 : 60|4@1+ (1,0) [0|15] ""  ADU

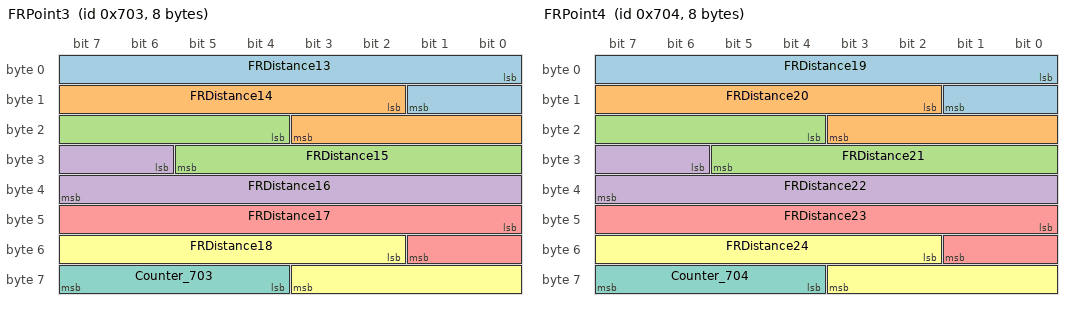
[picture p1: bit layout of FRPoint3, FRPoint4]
BO_ 1795 FRPoint3: 8 S32V
 SG_ FRDistance13 : 0|10@1+ (0.1,0) [0|102.3] "m"  ADU
 SG_ FRDistance14 : 10|10@1+ (0.1,0) [0|102.3] "m"  ADU
 SG_ FRDistance15 : 20|10@1+ (0.1,0) [0|102.3] "m"  ADU
 SG_ FRDistance16 : 30|10@1+ (0.1,0) [0|102.3] "m"  ADU
 SG_ FRDistance17 : 40|10@1+ (0.1,0) [0|102.3] "m"  ADU
 SG_ FRDistance18 : 50|10@1+ (0.1,0) [0|102.3] "m"  ADU
 SG_ Counter_703 : 60|4@1+ (1,0) [0|15] ""  ADU

BO_ 1796 FRPoint4: 8 S32V
 SG_ FRDistance19 : 0|10@1+ (0.1,0) [0|102.3] "m"  ADU
 SG_ FRDistance20 : 10|10@1+ (0.1,0) [0|102.3] "m"  ADU
 SG_ FRDistance21 : 20|10@1+ (0.1,0) [0|102.3] "m"  ADU
 SG_ FRDistance22 : 30|10@1+ (0.1,0) [0|102.3] "m"  ADU
 SG_ FRDistance23 : 40|10@1+ (0.1,0) [0|102.3] "m"  ADU
 SG_ FRDistance24 : 50|10@1+ (0.1,0) [0|102.3] "m"  ADU
 SG_ Counter_704 : 60|4@1+ (1,0) [0|15] ""  ADU

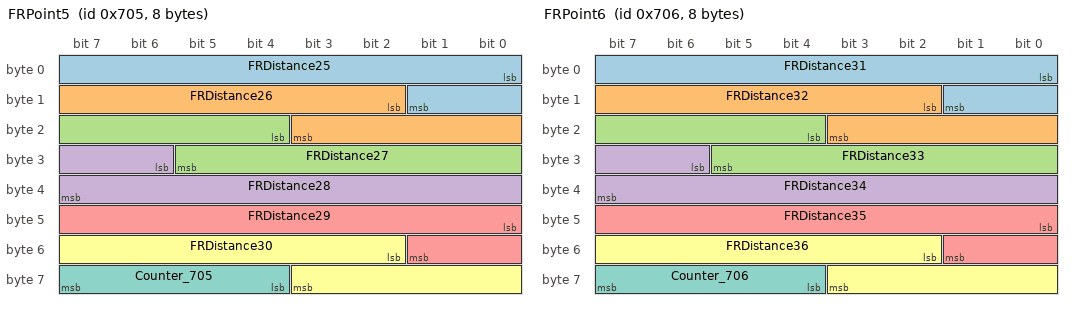
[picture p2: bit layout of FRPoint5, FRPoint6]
BO_ 1797 FRPoint5: 8 S32V
 SG_ FRDistance25 : 0|10@1+ (0.1,0) [0|102.3] "m"  ADU
 SG_ FRDistance26 : 10|10@1+ (0.1,0) [0|102.3] "m"  ADU
 SG_ FRDistance27 : 20|10@1+ (0.1,0) [0|102.3] "m"  ADU
 SG_ FRDistance28 : 30|10@1+ (0.1,0) [0|102.3] "m"  ADU
 SG_ FRDistance29 : 40|10@1+ (0.1,0) [0|102.3] "m"  ADU
 SG_ FRDistance30 : 50|10@1+ (0.1,0) [0|102.3] "m"  ADU
 SG_ Counter_705 : 60|4@1+ (1,0) [0|15] ""  ADU

BO_ 1798 FRPoint6: 8 S32V
 SG_ FRDistance31 : 0|10@1+ (0.1,0) [0|102.3] "m"  ADU
 SG_ FRDistance32 : 10|10@1+ (0.1,0) [0|102.3] "m"  ADU
 SG_ FRDistance33 : 20|10@1+ (0.1,0) [0|102.3] "m"  ADU
 SG_ FRDistance34 : 30|10@1+ (0.1,0) [0|102.3] "m"  ADU
 SG_ FRDistance35 : 40|10@1+ (0.1,0) [0|102.3] "m"  ADU
 SG_ FRDistance36 : 50|10@1+ (0.1,0) [0|102.3] "m"  ADU
 SG_ Counter_706 : 60|4@1+ (1,0) [0|15] ""  ADU

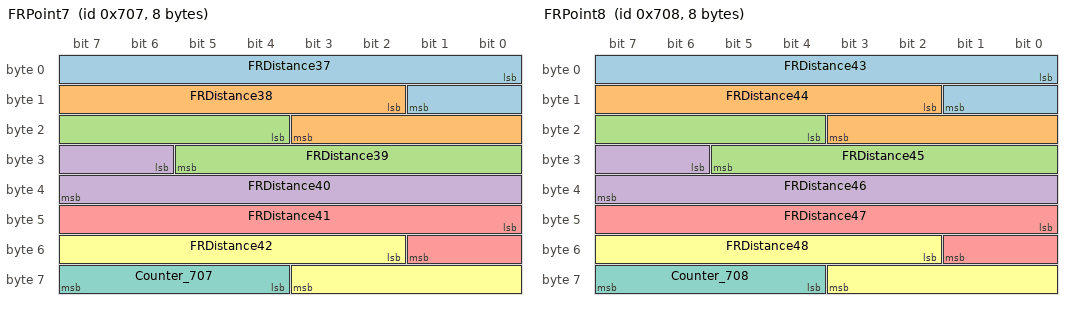
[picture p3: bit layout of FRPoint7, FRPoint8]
BO_ 1799 FRPoint7: 8 S32V
 SG_ FRDistance37 : 0|10@1+ (0.1,0) [0|102.3] "m"  ADU
 SG_ FRDistance38 : 10|10@1+ (0.1,0) [0|102.3] "m"  ADU
 SG_ FRDistance39 : 20|10@1+ (0.1,0) [0|102.3] "m"  ADU
 SG_ FRDistance40 : 30|10@1+ (0.1,0) [0|102.3] "m"  ADU
 SG_ FRDistance41 : 40|10@1+ (0.1,0) [0|102.3] "m"  ADU
 SG_ FRDistance42 : 50|10@1+ (0.1,0) [0|102.3] "m"  ADU
 SG_ Counter_707 : 60|4@1+ (1,0) [0|15] ""  ADU

BO_ 1800 FRPoint8: 8 S32V
 SG_ FRDistance43 : 0|10@1+ (0.1,0) [0|102.3] "m"  ADU
 SG_ FRDistance44 : 10|10@1+ (0.1,0) [0|102.3] "m"  ADU
 SG_ FRDistance45 : 20|10@1+ (0.1,0) [0|102.3] "m"  ADU
 SG_ FRDistance46 : 30|10@1+ (0.1,0) [0|102.3] "m"  ADU
 SG_ FRDistance47 : 40|10@1+ (0.1,0) [0|102.3] "m"  ADU
 SG_ FRDistance48 : 50|10@1+ (0.1,0) [0|102.3] "m"  ADU
 SG_ Counter_708 : 60|4@1+ (1,0) [0|15] ""  ADU

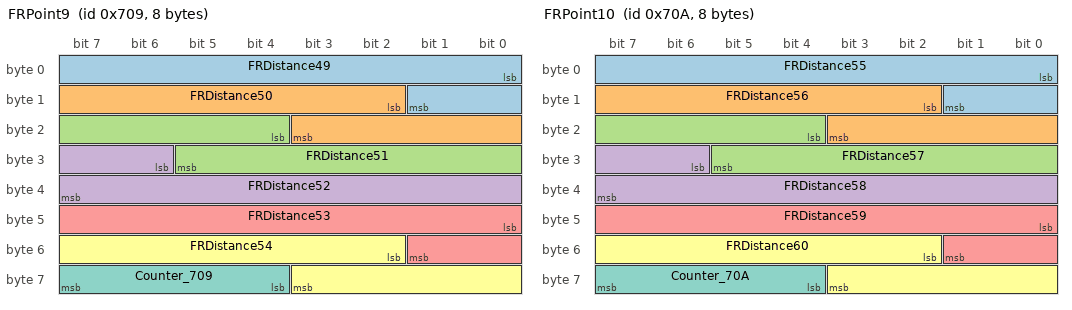
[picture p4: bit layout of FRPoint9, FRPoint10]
BO_ 1801 FRPoint9: 8 S32V
 SG_ FRDistance49 : 0|10@1+ (0.1,0) [0|102.3] "m"  ADU
 SG_ FRDistance50 : 10|10@1+ (0.1,0) [0|102.3] "m"  ADU
 SG_ FRDistance51 : 20|10@1+ (0.1,0) [0|102.3] "m"  ADU
 SG_ FRDistance52 : 30|10@1+ (0.1,0) [0|102.3] "m"  ADU
 SG_ FRDistance53 : 40|10@1+ (0.1,0) [0|102.3] "m"  ADU
 SG_ FRDistance54 : 50|10@1+ (0.1,0) [0|102.3] "m"  ADU
 SG_ Counter_709 : 60|4@1+ (1,0) [0|15] ""  ADU

BO_ 1802 FRPoint10: 8 S32V
 SG_ FRDistance55 : 0|10@1+ (0.1,0) [0|102.3] "m"  ADU
 SG_ FRDistance56 : 10|10@1+ (0.1,0) [0|102.3] "m"  ADU
 SG_ FRDistance57 : 20|10@1+ (0.1,0) [0|102.3] "m"  ADU
 SG_ FRDistance58 : 30|10@1+ (0.1,0) [0|102.3] "m"  ADU
 SG_ FRDistance59 : 40|10@1+ (0.1,0) [0|102.3] "m"  ADU
 SG_ FRDistance60 : 50|10@1+ (0.1,0) [0|102.3] "m"  ADU
 SG_ Counter_70A : 60|4@1+ (1,0) [0|15] ""  ADU

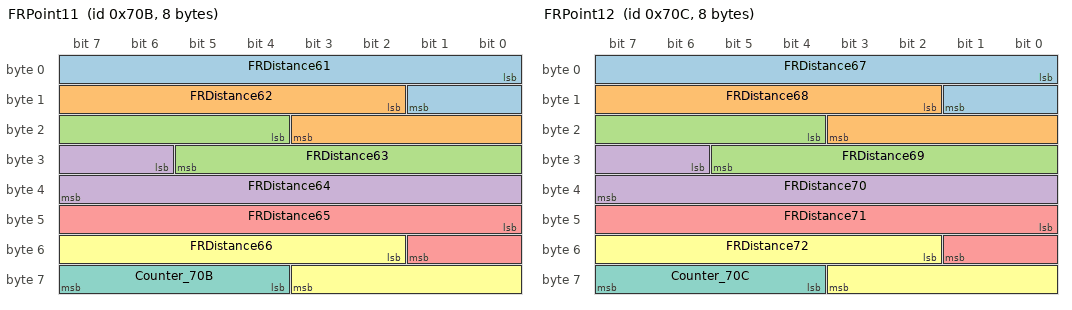
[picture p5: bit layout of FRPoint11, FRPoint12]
BO_ 1803 FRPoint11: 8 S32V
 SG_ FRDistance61 : 0|10@1+ (0.05,0) [0|51.15] "m"  ADU
 SG_ FRDistance62 : 10|10@1+ (0.05,0) [0|51.15] "m"  ADU
 SG_ FRDistance63 : 20|10@1+ (0.05,0) [0|51.15] "m"  ADU
 SG_ FRDistance64 : 30|10@1+ (0.05,0) [0|51.15] "m"  ADU
 SG_ FRDistance65 : 40|10@1+ (0.05,0) [0|51.15] "m"  ADU
 SG_ FRDistance66 : 50|10@1+ (0.05,0) [0|51.15] "m"  ADU
 SG_ Counter_70B : 60|4@1+ (1,0) [0|15] ""  ADU

BO_ 1804 FRPoint12: 8 S32V
 SG_ FRDistance67 : 0|10@1+ (0.05,0) [0|51.15] "m"  ADU
 SG_ FRDistance68 : 10|10@1+ (0.05,0) [0|51.15] "m"  ADU
 SG_ FRDistance69 : 20|10@1+ (0.05,0) [0|51.15] "m"  ADU
 SG_ FRDistance70 : 30|10@1+ (0.05,0) [0|51.15] "m"  ADU
 SG_ FRDistance71 : 40|10@1+ (0.05,0) [0|51.15] "m"  ADU
 SG_ FRDistance72 : 50|10@1+ (0.05,0) [0|51.15] "m"  ADU
 SG_ Counter_70C : 60|4@1+ (1,0) [0|15] ""  ADU

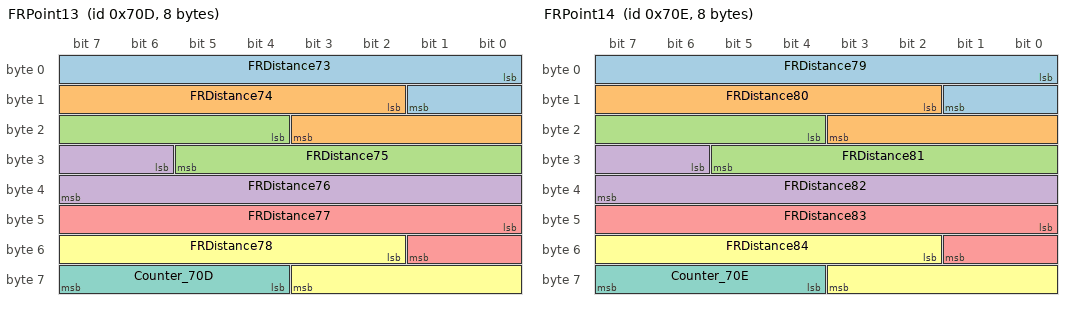
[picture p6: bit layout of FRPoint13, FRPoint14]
BO_ 1805 FRPoint13: 8 S32V
 SG_ FRDistance73 : 0|10@1+ (0.05,0) [0|51.15] "m"  ADU
 SG_ FRDistance74 : 10|10@1+ (0.05,0) [0|51.15] "m"  ADU
 SG_ FRDistance75 : 20|10@1+ (0.05,0) [0|51.15] "m"  ADU
 SG_ FRDistance76 : 30|10@1+ (0.05,0) [0|51.15] "m"  ADU
 SG_ FRDistance77 : 40|10@1+ (0.05,0) [0|51.15] "m"  ADU
 SG_ FRDistance78 : 50|10@1+ (0.05,0) [0|51.15] "m"  ADU
 SG_ Counter_70D : 60|4@1+ (1,0) [0|15] ""  ADU

BO_ 1806 FRPoint14: 8 S32V
 SG_ FRDistance79 : 0|10@1+ (0.05,0) [0|51.15] "m"  ADU
 SG_ FRDistance80 : 10|10@1+ (0.05,0) [0|51.15] "m"  ADU
 SG_ FRDistance81 : 20|10@1+ (0.05,0) [0|51.15] "m"  ADU
 SG_ FRDistance82 : 30|10@1+ (0.05,0) [0|51.15] "m"  ADU
 SG_ FRDistance83 : 40|10@1+ (0.05,0) [0|51.15] "m"  ADU
 SG_ FRDistance84 : 50|10@1+ (0.05,0) [0|51.15] "m"  ADU
 SG_ Counter_70E : 60|4@1+ (1,0) [0|15] ""  ADU

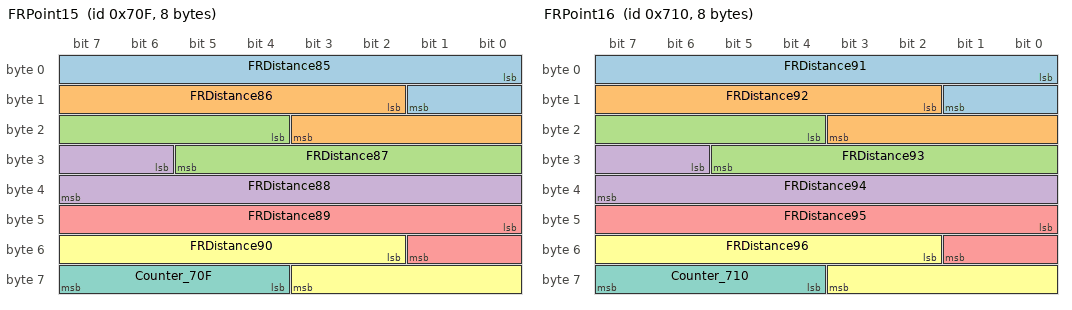
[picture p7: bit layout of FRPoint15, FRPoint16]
BO_ 1807 FRPoint15: 8 S32V
 SG_ FRDistance85 : 0|10@1+ (0.05,0) [0|51.15] "m"  ADU
 SG_ FRDistance86 : 10|10@1+ (0.05,0) [0|51.15] "m"  ADU
 SG_ FRDistance87 : 20|10@1+ (0.05,0) [0|51.15] "m"  ADU
 SG_ FRDistance88 : 30|10@1+ (0.05,0) [0|51.15] "m"  ADU
 SG_ FRDistance89 : 40|10@1+ (0.05,0) [0|51.15] "m"  ADU
 SG_ FRDistance90 : 50|10@1+ (0.05,0) [0|51.15] "m"  ADU
 SG_ Counter_70F : 60|4@1+ (1,0) [0|15] ""  ADU

BO_ 1808 FRPoint16: 8 S32V
 SG_ FRDistance91 : 0|10@1+ (0.05,0) [0|51.15] "m"  ADU
 SG_ FRDistance92 : 10|10@1+ (0.05,0) [0|51.15] "m"  ADU
 SG_ FRDistance93 : 20|10@1+ (0.05,0) [0|51.15] "m"  ADU
 SG_ FRDistance94 : 30|10@1+ (0.05,0) [0|51.15] "m"  ADU
 SG_ FRDistance95 : 40|10@1+ (0.05,0) [0|51.15] "m"  ADU
 SG_ FRDistance96 : 50|10@1+ (0.05,0) [0|51.15] "m"  ADU
 SG_ Counter_710 : 60|4@1+ (1,0) [0|15] ""  ADU

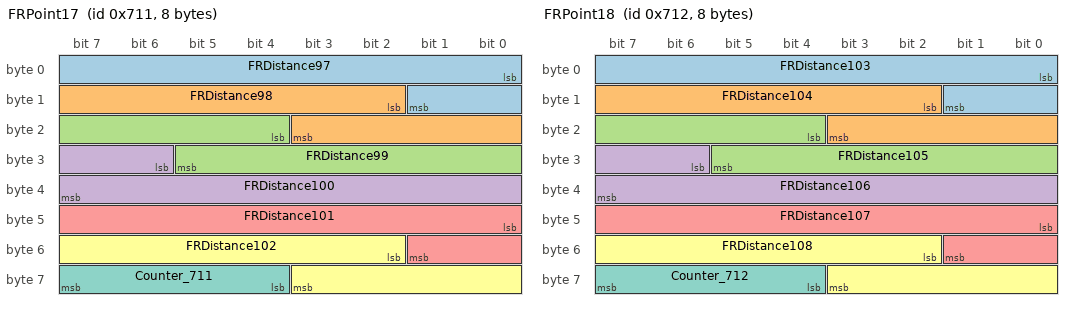
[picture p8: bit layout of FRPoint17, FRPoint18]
BO_ 1809 FRPoint17: 8 S32V
 SG_ FRDistance97 : 0|10@1+ (0.05,0) [0|51.15] "m"  ADU
 SG_ FRDistance98 : 10|10@1+ (0.05,0) [0|51.15] "m"  ADU
 SG_ FRDistance99 : 20|10@1+ (0.05,0) [0|51.15] "m"  ADU
 SG_ FRDistance100 : 30|10@1+ (0.05,0) [0|51.15] "m"  ADU
 SG_ FRDistance101 : 40|10@1+ (0.05,0) [0|51.15] "m"  ADU
 SG_ FRDistance102 : 50|10@1+ (0.05,0) [0|51.15] "m"  ADU
 SG_ Counter_711 : 60|4@1+ (1,0) [0|15] ""  ADU

BO_ 1810 FRPoint18: 8 S32V
 SG_ FRDistance103 : 0|10@1+ (0.05,0) [0|51.15] "m"  ADU
 SG_ FRDistance104 : 10|10@1+ (0.05,0) [0|51.15] "m"  ADU
 SG_ FRDistance105 : 20|10@1+ (0.05,0) [0|51.15] "m"  ADU
 SG_ FRDistance106 : 30|10@1+ (0.05,0) [0|51.15] "m"  ADU
 SG_ FRDistance107 : 40|10@1+ (0.05,0) [0|51.15] "m"  ADU
 SG_ FRDistance108 : 50|10@1+ (0.05,0) [0|51.15] "m"  ADU
 SG_ Counter_712 : 60|4@1+ (1,0) [0|15] ""  ADU

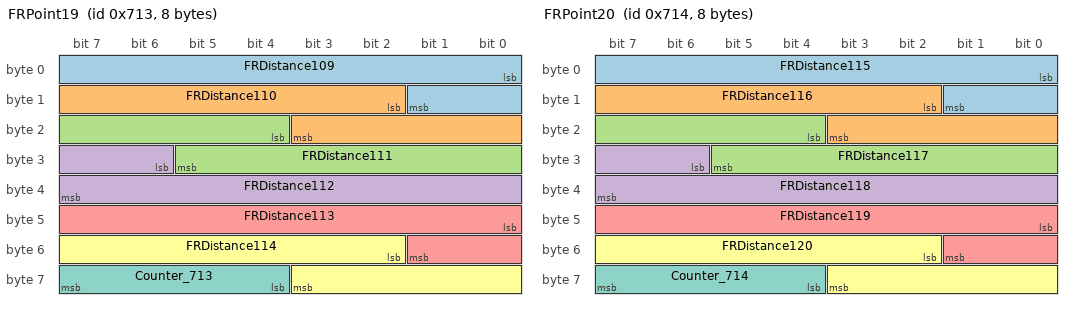
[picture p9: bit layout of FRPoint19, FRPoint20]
BO_ 1811 FRPoint19: 8 S32V
 SG_ FRDistance109 : 0|10@1+ (0.05,0) [0|51.15] "m"  ADU
 SG_ FRDistance110 : 10|10@1+ (0.05,0) [0|51.15] "m"  ADU
 SG_ FRDistance111 : 20|10@1+ (0.05,0) [0|51.15] "m"  ADU
 SG_ FRDistance112 : 30|10@1+ (0.05,0) [0|51.15] "m"  ADU
 SG_ FRDistance113 : 40|10@1+ (0.05,0) [0|51.15] "m"  ADU
 SG_ FRDistance114 : 50|10@1+ (0.05,0) [0|51.15] "m"  ADU
 SG_ Counter_713 : 60|4@1+ (1,0) [0|15] ""  ADU

BO_ 1812 FRPoint20: 8 S32V
 SG_ FRDistance115 : 0|10@1+ (0.05,0) [0|51.15] "m"  ADU
 SG_ FRDistance116 : 10|10@1+ (0.05,0) [0|51.15] "m"  ADU
 SG_ FRDistance117 : 20|10@1+ (0.05,0) [0|51.15] "m"  ADU
 SG_ FRDistance118 : 30|10@1+ (0.05,0) [0|51.15] "m"  ADU
 SG_ FRDistance119 : 40|10@1+ (0.05,0) [0|51.15] "m"  ADU
 SG_ FRDistance120 : 50|10@1+ (0.05,0) [0|51.15] "m"  ADU
 SG_ Counter_714 : 60|4@1+ (1,0) [0|15] ""  ADU

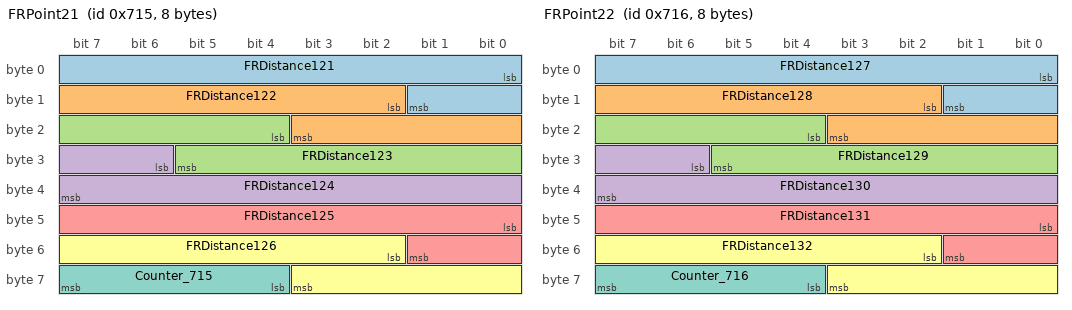
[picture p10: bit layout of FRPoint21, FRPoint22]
BO_ 1813 FRPoint21: 8 S32V
 SG_ FRDistance121 : 0|10@1+ (0.05,0) [0|51.15] "m"  ADU
 SG_ FRDistance122 : 10|10@1+ (0.05,0) [0|51.15] "m"  ADU
 SG_ FRDistance123 : 20|10@1+ (0.05,0) [0|51.15] "m"  ADU
 SG_ FRDistance124 : 30|10@1+ (0.05,0) [0|51.15] "m"  ADU
 SG_ FRDistance125 : 40|10@1+ (0.05,0) [0|51.15] "m"  ADU
 SG_ FRDistance126 : 50|10@1+ (0.05,0) [0|51.15] "m"  ADU
 SG_ Counter_715 : 60|4@1+ (1,0) [0|15] ""  ADU

BO_ 1814 FRPoint22: 8 S32V
 SG_ FRDistance127 : 0|10@1+ (0.05,0) [0|51.15] "m"  ADU
 SG_ FRDistance128 : 10|10@1+ (0.05,0) [0|51.15] "m"  ADU
 SG_ FRDistance129 : 20|10@1+ (0.05,0) [0|51.15] "m"  ADU
 SG_ FRDistance130 : 30|10@1+ (0.05,0) [0|51.15] "m"  ADU
 SG_ FRDistance131 : 40|10@1+ (0.05,0) [0|51.15] "m"  ADU
 SG_ FRDistance132 : 50|10@1+ (0.05,0) [0|51.15] "m"  ADU
 SG_ Counter_716 : 60|4@1+ (1,0) [0|15] ""  ADU

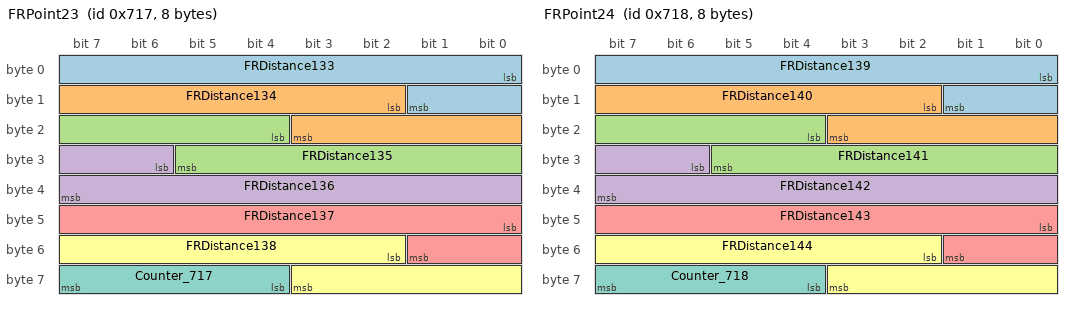
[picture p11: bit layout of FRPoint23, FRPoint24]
BO_ 1815 FRPoint23: 8 S32V
 SG_ FRDistance133 : 0|10@1+ (0.05,0) [0|51.15] "m"  ADU
 SG_ FRDistance134 : 10|10@1+ (0.05,0) [0|51.15] "m"  ADU
 SG_ FRDistance135 : 20|10@1+ (0.05,0) [0|51.15] "m"  ADU
 SG_ FRDistance136 : 30|10@1+ (0.05,0) [0|51.15] "m"  ADU
 SG_ FRDistance137 : 40|10@1+ (0.05,0) [0|51.15] "m"  ADU
 SG_ FRDistance138 : 50|10@1+ (0.05,0) [0|51.15] "m"  ADU
 SG_ Counter_717 : 60|4@1+ (1,0) [0|15] ""  ADU

BO_ 1816 FRPoint24: 8 S32V
 SG_ FRDistance139 : 0|10@1+ (0.05,0) [0|51.15] "m"  ADU
 SG_ FRDistance140 : 10|10@1+ (0.05,0) [0|51.15] "m"  ADU
 SG_ FRDistance141 : 20|10@1+ (0.05,0) [0|51.15] "m"  ADU
 SG_ FRDistance142 : 30|10@1+ (0.05,0) [0|51.15] "m"  ADU
 SG_ FRDistance143 : 40|10@1+ (0.05,0) [0|51.15] "m"  ADU
 SG_ FRDistance144 : 50|10@1+ (0.05,0) [0|51.15] "m"  ADU
 SG_ Counter_718 : 60|4@1+ (1,0) [0|15] ""  ADU

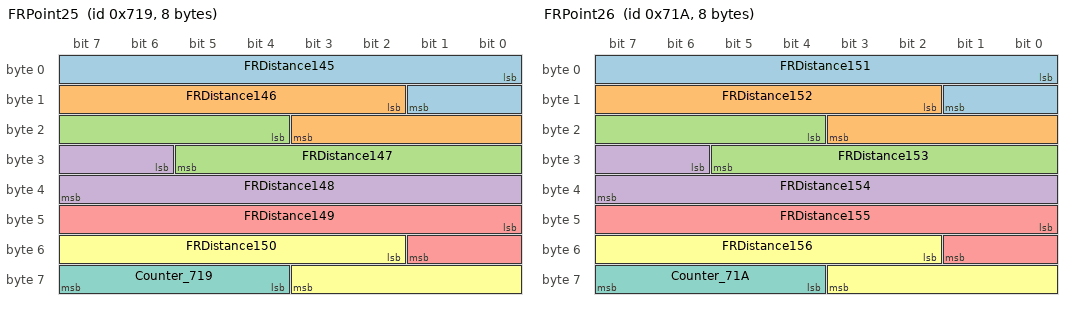
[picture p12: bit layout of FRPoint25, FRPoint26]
BO_ 1817 FRPoint25: 8 S32V
 SG_ FRDistance145 : 0|10@1+ (0.05,0) [0|51.15] "m"  ADU
 SG_ FRDistance146 : 10|10@1+ (0.05,0) [0|51.15] "m"  ADU
 SG_ FRDistance147 : 20|10@1+ (0.05,0) [0|51.15] "m"  ADU
 SG_ FRDistance148 : 30|10@1+ (0.05,0) [0|51.15] "m"  ADU
 SG_ FRDistance149 : 40|10@1+ (0.05,0) [0|51.15] "m"  ADU
 SG_ FRDistance150 : 50|10@1+ (0.05,0) [0|51.15] "m"  ADU
 SG_ Counter_719 : 60|4@1+ (1,0) [0|15] ""  ADU

BO_ 1818 FRPoint26: 8 S32V
 SG_ FRDistance151 : 0|10@1+ (0.05,0) [0|51.15] "m"  ADU
 SG_ FRDistance152 : 10|10@1+ (0.05,0) [0|51.15] "m"  ADU
 SG_ FRDistance153 : 20|10@1+ (0.05,0) [0|51.15] "m"  ADU
 SG_ FRDistance154 : 30|10@1+ (0.05,0) [0|51.15] "m"  ADU
 SG_ FRDistance155 : 40|10@1+ (0.05,0) [0|51.15] "m"  ADU
 SG_ FRDistance156 : 50|10@1+ (0.05,0) [0|51.15] "m"  ADU
 SG_ Counter_71A : 60|4@1+ (1,0) [0|15] ""  ADU

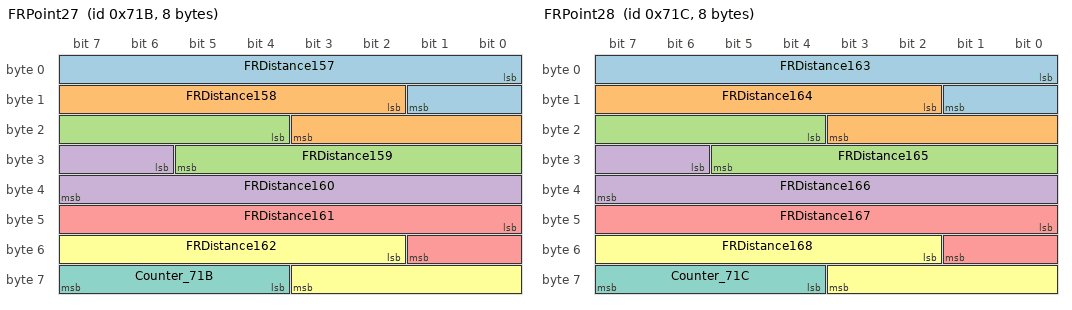
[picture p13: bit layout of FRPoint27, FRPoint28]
BO_ 1819 FRPoint27: 8 S32V
 SG_ FRDistance157 : 0|10@1+ (0.05,0) [0|51.15] "m"  ADU
 SG_ FRDistance158 : 10|10@1+ (0.05,0) [0|51.15] "m"  ADU
 SG_ FRDistance159 : 20|10@1+ (0.05,0) [0|51.15] "m"  ADU
 SG_ FRDistance160 : 30|10@1+ (0.05,0) [0|51.15] "m"  ADU
 SG_ FRDistance161 : 40|10@1+ (0.05,0) [0|51.15] "m"  ADU
 SG_ FRDistance162 : 50|10@1+ (0.05,0) [0|51.15] "m"  ADU
 SG_ Counter_71B : 60|4@1+ (1,0) [0|15] ""  ADU

BO_ 1820 FRPoint28: 8 S32V
 SG_ FRDistance163 : 0|10@1+ (0.05,0) [0|51.15] "m"  ADU
 SG_ FRDistance164 : 10|10@1+ (0.05,0) [0|51.15] "m"  ADU
 SG_ FRDistance165 : 20|10@1+ (0.05,0) [0|51.15] "m"  ADU
 SG_ FRDistance166 : 30|10@1+ (0.05,0) [0|51.15] "m"  ADU
 SG_ FRDistance167 : 40|10@1+ (0.05,0) [0|51.15] "m"  ADU
 SG_ FRDistance168 : 50|10@1+ (0.05,0) [0|51.15] "m"  ADU
 SG_ Counter_71C : 60|4@1+ (1,0) [0|15] ""  ADU

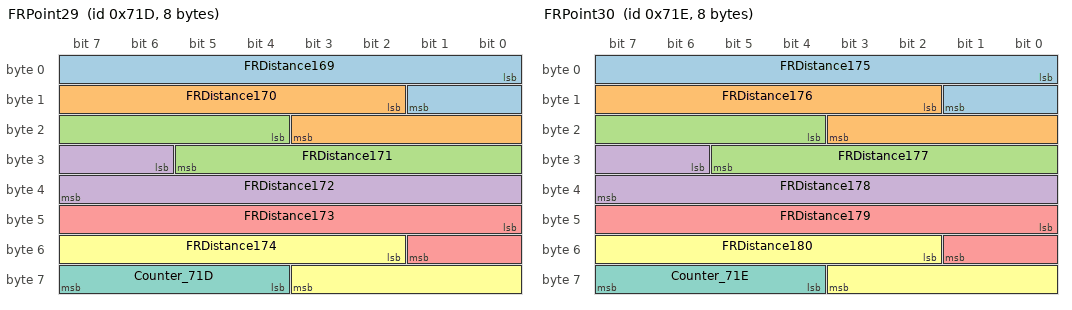
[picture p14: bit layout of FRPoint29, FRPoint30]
BO_ 1821 FRPoint29: 8 S32V
 SG_ FRDistance169 : 0|10@1+ (0.05,0) [0|51.15] "m"  ADU
 SG_ FRDistance170 : 10|10@1+ (0.05,0) [0|51.15] "m"  ADU
 SG_ FRDistance171 : 20|10@1+ (0.05,0) [0|51.15] "m"  ADU
 SG_ FRDistance172 : 30|10@1+ (0.05,0) [0|51.15] "m"  ADU
 SG_ FRDistance173 : 40|10@1+ (0.05,0) [0|51.15] "m"  ADU
 SG_ FRDistance174 : 50|10@1+ (0.05,0) [0|51.15] "m"  ADU
 SG_ Counter_71D : 60|4@1+ (1,0) [0|15] ""  ADU

BO_ 1822 FRPoint30: 8 S32V
 SG_ FRDistance175 : 0|10@1+ (0.05,0) [0|51.15] "m"  ADU
 SG_ FRDistance176 : 10|10@1+ (0.05,0) [0|51.15] "m"  ADU
 SG_ FRDistance177 : 20|10@1+ (0.05,0) [0|51.15] "m"  ADU
 SG_ FRDistance178 : 30|10@1+ (0.05,0) [0|51.15] "m"  ADU
 SG_ FRDistance179 : 40|10@1+ (0.05,0) [0|51.15] "m"  ADU
 SG_ FRDistance180 : 50|10@1+ (0.05,0) [0|51.15] "m"  ADU
 SG_ Counter_71E : 60|4@1+ (1,0) [0|15] ""  ADU

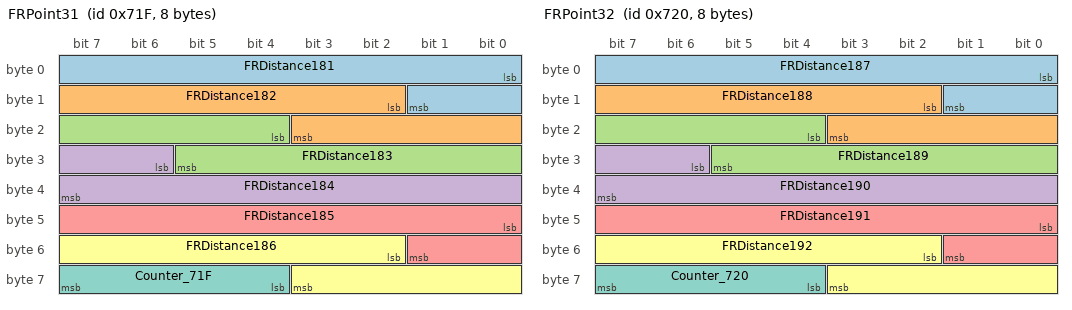
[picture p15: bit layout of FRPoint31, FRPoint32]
BO_ 1823 FRPoint31: 8 S32V
 SG_ FRDistance181 : 0|10@1+ (0.05,0) [0|51.15] "m"  ADU
 SG_ FRDistance182 : 10|10@1+ (0.05,0) [0|51.15] "m"  ADU
 SG_ FRDistance183 : 20|10@1+ (0.05,0) [0|51.15] "m"  ADU
 SG_ FRDistance184 : 30|10@1+ (0.05,0) [0|51.15] "m"  ADU
 SG_ FRDistance185 : 40|10@1+ (0.05,0) [0|51.15] "m"  ADU
 SG_ FRDistance186 : 50|10@1+ (0.05,0) [0|51.15] "m"  ADU
 SG_ Counter_71F : 60|4@1+ (1,0) [0|15] ""  ADU

BO_ 1824 FRPoint32: 8 S32V
 SG_ FRDistance187 : 0|10@1+ (0.05,0) [0|51.15] "m"  ADU
 SG_ FRDistance188 : 10|10@1+ (0.05,0) [0|51.15] "m"  ADU
 SG_ FRDistance189 : 20|10@1+ (0.05,0) [0|51.15] "m"  ADU
 SG_ FRDistance190 : 30|10@1+ (0.05,0) [0|51.15] "m"  ADU
 SG_ FRDistance191 : 40|10@1+ (0.05,0) [0|51.15] "m"  ADU
 SG_ FRDistance192 : 50|10@1+ (0.05,0) [0|51.15] "m"  ADU
 SG_ Counter_720 : 60|4@1+ (1,0) [0|15] ""  ADU

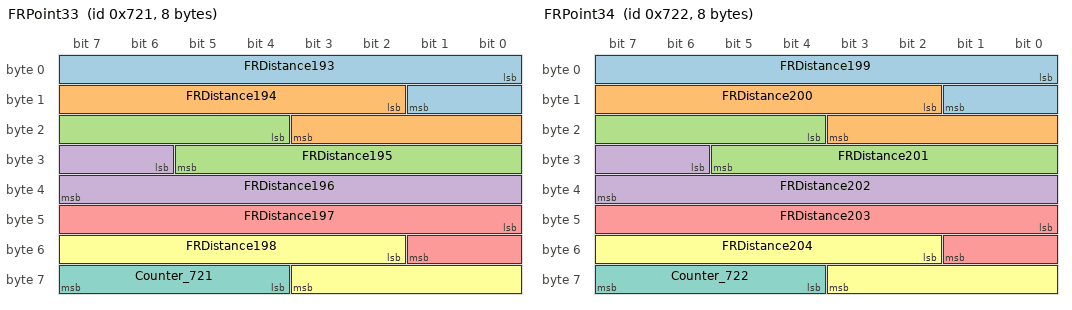
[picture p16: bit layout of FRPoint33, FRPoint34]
BO_ 1825 FRPoint33: 8 S32V
 SG_ FRDistance193 : 0|10@1+ (0.05,0) [0|51.15] "m"  ADU
 SG_ FRDistance194 : 10|10@1+ (0.05,0) [0|51.15] "m"  ADU
 SG_ FRDistance195 : 20|10@1+ (0.05,0) [0|51.15] "m"  ADU
 SG_ FRDistance196 : 30|10@1+ (0.05,0) [0|51.15] "m"  ADU
 SG_ FRDistance197 : 40|10@1+ (0.05,0) [0|51.15] "m"  ADU
 SG_ FRDistance198 : 50|10@1+ (0.05,0) [0|51.15] "m"  ADU
 SG_ Counter_721 : 60|4@1+ (1,0) [0|15] ""  ADU

BO_ 1826 FRPoint34: 8 S32V
 SG_ FRDistance199 : 0|10@1+ (0.05,0) [0|51.15] "m"  ADU
 SG_ FRDistance200 : 10|10@1+ (0.05,0) [0|51.15] "m"  ADU
 SG_ FRDistance201 : 20|10@1+ (0.05,0) [0|51.15] "m"  ADU
 SG_ FRDistance202 : 30|10@1+ (0.05,0) [0|51.15] "m"  ADU
 SG_ FRDistance203 : 40|10@1+ (0.05,0) [0|51.15] "m"  ADU
 SG_ FRDistance204 : 50|10@1+ (0.05,0) [0|51.15] "m"  ADU
 SG_ Counter_722 : 60|4@1+ (1,0) [0|15] ""  ADU

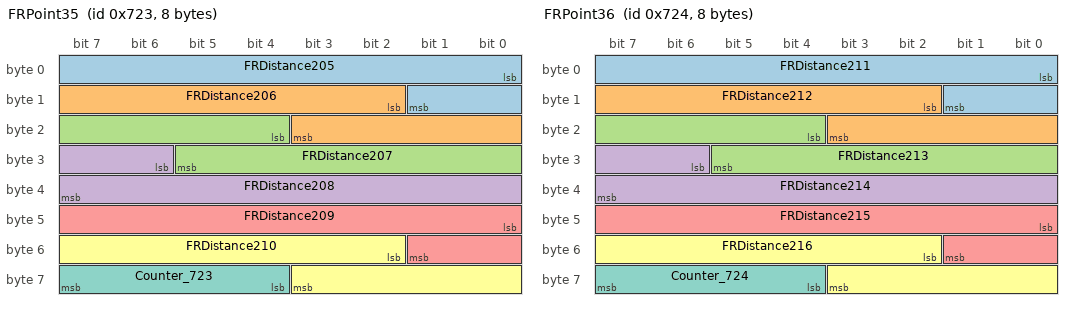
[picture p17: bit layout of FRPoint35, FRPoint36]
BO_ 1827 FRPoint35: 8 S32V
 SG_ FRDistance205 : 0|10@1+ (0.05,0) [0|51.15] "m"  ADU
 SG_ FRDistance206 : 10|10@1+ (0.05,0) [0|51.15] "m"  ADU
 SG_ FRDistance207 : 20|10@1+ (0.05,0) [0|51.15] "m"  ADU
 SG_ FRDistance208 : 30|10@1+ (0.05,0) [0|51.15] "m"  ADU
 SG_ FRDistance209 : 40|10@1+ (0.05,0) [0|51.15] "m"  ADU
 SG_ FRDistance210 : 50|10@1+ (0.05,0) [0|51.15] "m"  ADU
 SG_ Counter_723 : 60|4@1+ (1,0) [0|15] ""  ADU

BO_ 1828 FRPoint36: 8 S32V
 SG_ FRDistance211 : 0|10@1+ (0.05,0) [0|51.15] "m"  ADU
 SG_ FRDistance212 : 10|10@1+ (0.05,0) [0|51.15] "m"  ADU
 SG_ FRDistance213 : 20|10@1+ (0.05,0) [0|51.15] "m"  ADU
 SG_ FRDistance214 : 30|10@1+ (0.05,0) [0|51.15] "m"  ADU
 SG_ FRDistance215 : 40|10@1+ (0.05,0) [0|51.15] "m"  ADU
 SG_ FRDistance216 : 50|10@1+ (0.05,0) [0|51.15] "m"  ADU
 SG_ Counter_724 : 60|4@1+ (1,0) [0|15] ""  ADU

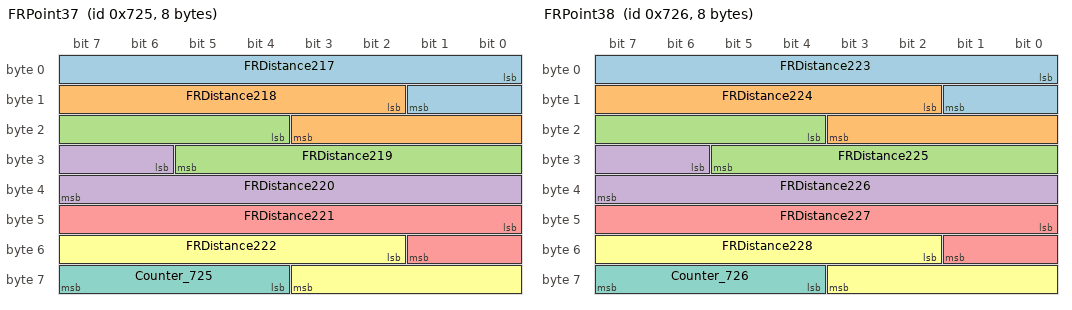
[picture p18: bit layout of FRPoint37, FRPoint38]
BO_ 1829 FRPoint37: 8 S32V
 SG_ FRDistance217 : 0|10@1+ (0.05,0) [0|51.15] "m"  ADU
 SG_ FRDistance218 : 10|10@1+ (0.05,0) [0|51.15] "m"  ADU
 SG_ FRDistance219 : 20|10@1+ (0.05,0) [0|51.15] "m"  ADU
 SG_ FRDistance220 : 30|10@1+ (0.05,0) [0|51.15] "m"  ADU
 SG_ FRDistance221 : 40|10@1+ (0.05,0) [0|51.15] "m"  ADU
 SG_ FRDistance222 : 50|10@1+ (0.05,0) [0|51.15] "m"  ADU
 SG_ Counter_725 : 60|4@1+ (1,0) [0|15] ""  ADU

BO_ 1830 FRPoint38: 8 S32V
 SG_ FRDistance223 : 0|10@1+ (0.05,0) [0|51.15] "m"  ADU
 SG_ FRDistance224 : 10|10@1+ (0.05,0) [0|51.15] "m"  ADU
 SG_ FRDistance225 : 20|10@1+ (0.05,0) [0|51.15] "m"  ADU
 SG_ FRDistance226 : 30|10@1+ (0.05,0) [0|51.15] "m"  ADU
 SG_ FRDistance227 : 40|10@1+ (0.05,0) [0|51.15] "m"  ADU
 SG_ FRDistance228 : 50|10@1+ (0.05,0) [0|51.15] "m"  ADU
 SG_ Counter_726 : 60|4@1+ (1,0) [0|15] ""  ADU

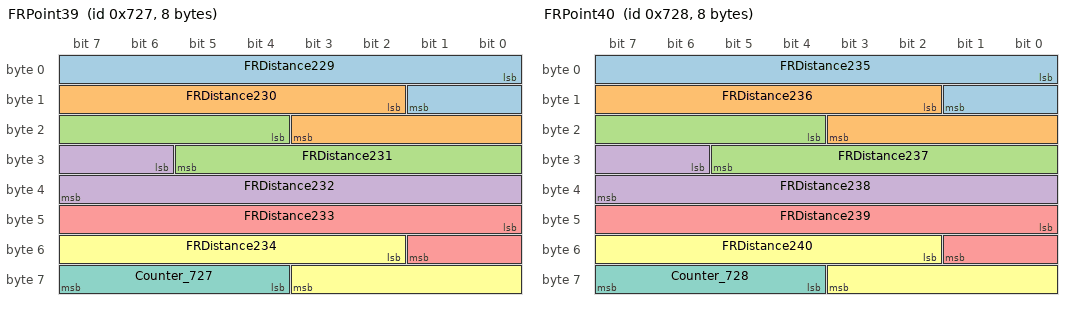
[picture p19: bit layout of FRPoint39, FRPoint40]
BO_ 1831 FRPoint39: 8 S32V
 SG_ FRDistance229 : 0|10@1+ (0.05,0) [0|51.15] "m"  ADU
 SG_ FRDistance230 : 10|10@1+ (0.05,0) [0|51.15] "m"  ADU
 SG_ FRDistance231 : 20|10@1+ (0.05,0) [0|51.15] "m"  ADU
 SG_ FRDistance232 : 30|10@1+ (0.05,0) [0|51.15] "m"  ADU
 SG_ FRDistance233 : 40|10@1+ (0.05,0) [0|51.15] "m"  ADU
 SG_ FRDistance234 : 50|10@1+ (0.05,0) [0|51.15] "m"  ADU
 SG_ Counter_727 : 60|4@1+ (1,0) [0|15] ""  ADU

BO_ 1832 FRPoint40: 8 S32V
 SG_ FRDistance235 : 0|10@1+ (0.05,0) [0|51.15] "m"  ADU
 SG_ FRDistance236 : 10|10@1+ (0.05,0) [0|51.15] "m"  ADU
 SG_ FRDistance237 : 20|10@1+ (0.05,0) [0|51.15] "m"  ADU
 SG_ FRDistance238 : 30|10@1+ (0.05,0) [0|51.15] "m"  ADU
 SG_ FRDistance239 : 40|10@1+ (0.05,0) [0|51.15] "m"  ADU
 SG_ FRDistance240 : 50|10@1+ (0.05,0) [0|51.15] "m"  ADU
 SG_ Counter_728 : 60|4@1+ (1,0) [0|15] ""  ADU

BO_ 1833 FRPoint41: 8 S32V
 SG_ FRDistance241 : 0|10@1+ (0.05,0) [0|51.15] "m"  ADU
 SG_ FRDistance242 : 10|10@1+ (0.05,0) [0|51.15] "m"  ADU
 SG_ FRDistance243 : 20|10@1+ (0.05,0) [0|51.15] "m"  ADU
 SG_ FRDistance244 : 30|10@1+ (0.05,0) [0|51.15] "m"  ADU
 SG_ FRDistance245 : 40|10@1+ (0.05,0) [0|51.15] "m"  ADU
 SG_ FRDistance246 : 50|10@1+ (0.05,0) [0|51.15] "m"  ADU
 SG_ Counter_729 : 60|4@1+ (1,0) [0|15] ""  ADU

BO_ 1834 FRPoint42: 8 S32V
 SG_ FRDistance247 : 0|10@1+ (0.05,0) [0|51.15] "m"  ADU
 SG_ FRDistance248 : 10|10@1+ (0.05,0) [0|51.15] "m"  ADU
 SG_ FRDistance249 : 20|10@1+ (0.05,0) [0|51.15] "m"  ADU
 SG_ FRDistance250 : 30|10@1+ (0.05,0) [0|51.15] "m"  ADU
 SG_ FRDistance251 : 40|10@1+ (0.05,0) [0|51.15] "m"  ADU
 SG_ FRDistance252 : 50|10@1+ (0.05,0) [0|51.15] "m"  ADU
 SG_ Counter_72A : 60|4@1+ (1,0) [0|15] ""  ADU

BO_ 1835 FRPoint43: 8 S32V
 SG_ FRDistance253 : 0|10@1+ (0.05,0) [0|51.15] "m"  ADU
 SG_ FRDistance254 : 10|10@1+ (0.05,0) [0|51.15] "m"  ADU
 SG_ FRDistance255 : 20|10@1+ (0.05,0) [0|51.15] "m"  ADU
 SG_ FRDistance256 : 30|10@1+ (0.05,0) [0|51.15] "m"  ADU
 SG_ FRDistance257 : 40|10@1+ (0.05,0) [0|51.15] "m"  ADU
 SG_ FRDistance258 : 50|10@1+ (0.05,0) [0|51.15] "m"  ADU
 SG_ Counter_72B : 60|4@1+ (1,0) [0|15] ""  ADU

BO_ 1836 FRPoint44: 8 S32V
 SG_ FRDistance259 : 0|10@1+ (0.05,0) [0|51.15] "m"  ADU
 SG_ FRDistance260 : 10|10@1+ (0.05,0) [0|51.15] "m"  ADU
 SG_ FRDistance261 : 20|10@1+ (0.05,0) [0|51.15] "m"  ADU
 SG_ FRDistance262 : 30|10@1+ (0.05,0) [0|51.15] "m"  ADU
 SG_ FRDistance263 : 40|10@1+ (0.05,0) [0|51.15] "m"  ADU
 SG_ FRDistance264 : 50|10@1+ (0.05,0) [0|51.15] "m"  ADU
 SG_ Counter_72C : 60|4@1+ (1,0) [0|15] ""  ADU

BO_ 1837 FRPoint45: 8 S32V
 SG_ FRDistance265 : 0|10@1+ (0.05,0) [0|51.15] "m"  ADU
 SG_ FRDistance266 : 10|10@1+ (0.05,0) [0|51.15] "m"  ADU
 SG_ FRDistance267 : 20|10@1+ (0.05,0) [0|51.15] "m"  ADU
 SG_ FRDistance268 : 30|10@1+ (0.05,0) [0|51.15] "m"  ADU
 SG_ FRDistance269 : 40|10@1+ (0.05,0) [0|51.15] "m"  ADU
 SG_ FRDistance270 : 50|10@1+ (0.05,0) [0|51.15] "m"  ADU
 SG_ Counter_72D : 60|4@1+ (1,0) [0|15] ""  ADU

BO_ 1838 FRPoint46: 8 S32V
 SG_ FRDistance271 : 0|10@1+ (0.05,0) [0|51.15] "m"  ADU
 SG_ FRDistance272 : 10|10@1+ (0.05,0) [0|51.15] "m"  ADU
 SG_ FRDistance273 : 20|10@1+ (0.05,0) [0|51.15] "m"  ADU
 SG_ FRDistance274 : 30|10@1+ (0.05,0) [0|51.15] "m"  ADU
 SG_ FRDistance275 : 40|10@1+ (0.05,0) [0|51.15] "m"  ADU
 SG_ FRDistance276 : 50|10@1+ (0.05,0) [0|51.15] "m"  ADU
 SG_ Counter_72E : 60|4@1+ (1,0) [0|15] ""  ADU

BO_ 1839 FRPoint47: 8 S32V
 SG_ FRDistance277 : 0|10@1+ (0.05,0) [0|51.15] "m"  ADU
 SG_ FRDistance278 : 10|10@1+ (0.05,0) [0|51.15] "m"  ADU
 SG_ FRDistance279 : 20|10@1+ (0.05,0) [0|51.15] "m"  ADU
 SG_ FRDistance280 : 30|10@1+ (0.05,0) [0|51.15] "m"  ADU
 SG_ FRDistance281 : 40|10@1+ (0.05,0) [0|51.15] "m"  ADU
 SG_ FRDistance282 : 50|10@1+ (0.05,0) [0|51.15] "m"  ADU
 SG_ Counter_72F : 60|4@1+ (1,0) [0|15] ""  ADU

BO_ 1840 FRPoint48: 8 S32V
 SG_ FRDistance283 : 0|10@1+ (0.05,0) [0|51.15] "m"  ADU
 SG_ FRDistance284 : 10|10@1+ (0.05,0) [0|51.15] "m"  ADU
 SG_ FRDistance285 : 20|10@1+ (0.05,0) [0|51.15] "m"  ADU
 SG_ FRDistance286 : 30|10@1+ (0.05,0) [0|51.15] "m"  ADU
 SG_ FRDistance287 : 40|10@1+ (0.05,0) [0|51.15] "m"  ADU
 SG_ FRDistance288 : 50|10@1+ (0.05,0) [0|51.15] "m"  ADU
 SG_ Counter_730 : 60|4@1+ (1,0) [0|15] ""  ADU

BO_ 1841 FRPoint49: 8 S32V
 SG_ FRDistance289 : 0|10@1+ (0.05,0) [0|51.15] "m"  ADU
 SG_ FRDistance290 : 10|10@1+ (0.05,0) [0|51.15] "m"  ADU
 SG_ FRDistance291 : 20|10@1+ (0.05,0) [0|51.15] "m"  ADU
 SG_ FRDistance292 : 30|10@1+ (0.05,0) [0|51.15] "m"  ADU
 SG_ FRDistance293 : 40|10@1+ (0.05,0) [0|51.15] "m"  ADU
 SG_ FRDistance294 : 50|10@1+ (0.05,0) [0|51.15] "m"  ADU
 SG_ Counter_731 : 60|4@1+ (1,0) [0|15] ""  ADU

BO_ 1842 FRPoint50: 8 S32V
 SG_ FRDistance295 : 0|10@1+ (0.05,0) [0|51.15] "m"  ADU
 SG_ FRDistance296 : 10|10@1+ (0.05,0) [0|51.15] "m"  ADU
 SG_ FRDistance297 : 20|10@1+ (0.05,0) [0|51.15] "m"  ADU
 SG_ FRDistance298 : 30|10@1+ (0.05,0) [0|51.15] "m"  ADU
 SG_ FRDistance299 : 40|10@1+ (0.05,0) [0|51.15] "m"  ADU
 SG_ FRDistance300 : 50|10@1+ (0.05,0) [0|51.15] "m"  ADU
 SG_ Counter_732 : 60|4@1+ (1,0) [0|15] ""  ADU

BO_ 1843 FRPoint51: 8 S32V
 SG_ FRDistance301 : 0|10@1+ (0.1,0) [0|102.3] "m"  ADU
 SG_ FRDistance302 : 10|10@1+ (0.1,0) [0|102.3] "m"  ADU
 SG_ FRDistance303 : 20|10@1+ (0.1,0) [0|102.3] "m"  ADU
 SG_ FRDistance304 : 30|10@1+ (0.1,0) [0|102.3] "m"  ADU
 SG_ FRDistance305 : 40|10@1+ (0.1,0) [0|102.3] "m"  ADU
 SG_ FRDistance306 : 50|10@1+ (0.1,0) [0|102.3] "m"  ADU
 SG_ Counter_733 : 60|4@1+ (1,0) [0|15] ""  ADU

BO_ 1844 FRPoint52: 8 S32V
 SG_ FRDistance307 : 0|10@1+ (0.1,0) [0|102.3] "m"  ADU
 SG_ FRDistance308 : 10|10@1+ (0.1,0) [0|102.3] "m"  ADU
 SG_ FRDistance309 : 20|10@1+ (0.1,0) [0|102.3] "m"  ADU
 SG_ FRDistance310 : 30|10@1+ (0.1,0) [0|102.3] "m"  ADU
 SG_ FRDistance311 : 40|10@1+ (0.1,0) [0|102.3] "m"  ADU
 SG_ FRDistance312 : 50|10@1+ (0.1,0) [0|102.3] "m"  ADU
 SG_ Counter_734 : 60|4@1+ (1,0) [0|15] ""  ADU

BO_ 1845 FRPoint53: 8 S32V
 SG_ FRDistance313 : 0|10@1+ (0.1,0) [0|102.3] "m"  ADU
 SG_ FRDistance314 : 10|10@1+ (0.1,0) [0|102.3] "m"  ADU
 SG_ FRDistance315 : 20|10@1+ (0.1,0) [0|102.3] "m"  ADU
 SG_ FRDistance316 : 30|10@1+ (0.1,0) [0|102.3] "m"  ADU
 SG_ FRDistance317 : 40|10@1+ (0.1,0) [0|102.3] "m"  ADU
 SG_ FRDistance318 : 50|10@1+ (0.1,0) [0|102.3] "m"  ADU
 SG_ Counter_735 : 60|4@1+ (1,0) [0|15] ""  ADU

BO_ 1846 FRPoint54: 8 S32V
 SG_ FRDistance319 : 0|10@1+ (0.1,0) [0|102.3] "m"  ADU
 SG_ FRDistance320 : 10|10@1+ (0.1,0) [0|102.3] "m"  ADU
 SG_ FRDistance321 : 20|10@1+ (0.1,0) [0|102.3] "m"  ADU
 SG_ FRDistance322 : 30|10@1+ (0.1,0) [0|102.3] "m"  ADU
 SG_ FRDistance323 : 40|10@1+ (0.1,0) [0|102.3] "m"  ADU
 SG_ FRDistance324 : 50|10@1+ (0.1,0) [0|102.3] "m"  ADU
 SG_ Counter_736 : 60|4@1+ (1,0) [0|15] ""  ADU

BO_ 1847 FRPoint55: 8 S32V
 SG_ FRDistance325 : 0|10@1+ (0.1,0) [0|102.3] "m"  ADU
 SG_ FRDistance326 : 10|10@1+ (0.1,0) [0|102.3] "m"  ADU
 SG_ FRDistance327 : 20|10@1+ (0.1,0) [0|102.3] "m"  ADU
 SG_ FRDistance328 : 30|10@1+ (0.1,0) [0|102.3] "m"  ADU
 SG_ FRDistance329 : 40|10@1+ (0.1,0) [0|102.3] "m"  ADU
 SG_ FRDistance330 : 50|10@1+ (0.1,0) [0|102.3] "m"  ADU
 SG_ Counter_737 : 60|4@1+ (1,0) [0|15] ""  ADU

BO_ 1848 FRPoint56: 8 S32V
 SG_ FRDistance331 : 0|10@1+ (0.1,0) [0|102.3] "m"  ADU
 SG_ FRDistance332 : 10|10@1+ (0.1,0) [0|102.3] "m"  ADU
 SG_ FRDistance333 : 20|10@1+ (0.1,0) [0|102.3] "m"  ADU
 SG_ FRDistance334 : 30|10@1+ (0.1,0) [0|102.3] "m"  ADU
 SG_ FRDistance335 : 40|10@1+ (0.1,0) [0|102.3] "m"  ADU
 SG_ FRDistance336 : 50|10@1+ (0.1,0) [0|102.3] "m"  ADU
 SG_ Counter_738 : 60|4@1+ (1,0) [0|15] ""  ADU

BO_ 1849 FRPoint57: 8 S32V
 SG_ FRDistance337 : 0|10@1+ (0.1,0) [0|102.3] "m"  ADU
 SG_ FRDistance338 : 10|10@1+ (0.1,0) [0|102.3] "m"  ADU
 SG_ FRDistance339 : 20|10@1+ (0.1,0) [0|102.3] "m"  ADU
 SG_ FRDistance340 : 30|10@1+ (0.1,0) [0|102.3] "m"  ADU
 SG_ FRDistance341 : 40|10@1+ (0.1,0) [0|102.3] "m"  ADU
 SG_ FRDistance342 : 50|10@1+ (0.1,0) [0|102.3] "m"  ADU
 SG_ Counter_739 : 60|4@1+ (1,0) [0|15] ""  ADU

BO_ 1850 FRPoint58: 8 S32V
 SG_ FRDistance343 : 0|10@1+ (0.1,0) [0|102.3] "m"  ADU
 SG_ FRDistance344 : 10|10@1+ (0.1,0) [0|102.3] "m"  ADU
 SG_ FRDistance345 : 20|10@1+ (0.1,0) [0|102.3] "m"  ADU
 SG_ FRDistance346 : 30|10@1+ (0.1,0) [0|102.3] "m"  ADU
 SG_ FRDistance347 : 40|10@1+ (0.1,0) [0|102.3] "m"  ADU
 SG_ FRDistance348 : 50|10@1+ (0.1,0) [0|102.3] "m"  ADU
 SG_ Counter_73A : 60|4@1+ (1,0) [0|15] ""  ADU

BO_ 1851 FRPoint59: 8 S32V
 SG_ FRDistance349 : 0|10@1+ (0.1,0) [0|102.3] "m"  ADU
 SG_ FRDistance350 : 10|10@1+ (0.1,0) [0|102.3] "m"  ADU
 SG_ FRDistance351 : 20|10@1+ (0.1,0) [0|102.3] "m"  ADU
 SG_ FRDistance352 : 30|10@1+ (0.1,0) [0|102.3] "m"  ADU
 SG_ FRDistance353 : 40|10@1+ (0.1,0) [0|102.3] "m"  ADU
 SG_ FRDistance354 : 50|10@1+ (0.1,0) [0|102.3] "m"  ADU
 SG_ Counter_73B : 60|4@1+ (1,0) [0|15] ""  ADU

BO_ 1852 FRPoint60: 8 S32V
 SG_ FRDistance355 : 0|10@1+ (0.1,0) [0|102.3] "m"  ADU
 SG_ FRDistance356 : 10|10@1+ (0.1,0) [0|102.3] "m"  ADU
 SG_ FRDistance357 : 20|10@1+ (0.1,0) [0|102.3] "m"  ADU
 SG_ FRDistance358 : 30|10@1+ (0.1,0) [0|102.3] "m"  ADU
 SG_ FRDistance359 : 40|10@1+ (0.1,0) [0|102.3] "m"  ADU
 SG_ FRDistance360 : 50|10@1+ (0.1,0) [0|102.3] "m"  ADU
 SG_ Counter_73C : 60|4@1+ (1,0) [0|15] ""  ADU

CM_ "Version:V1.0,Date:2018/12/26,Author:Zhang Hai,Check:,Review:,Approval:,Description:()Initial version.;
 ";
CM_ BO_ 3221225472 "This is a message for not used signals, created by Vector CANdb++ DBC OLE DB Provider.";
CM_ SG_ 3221225472 number_of_objects "点数量";
CM_ SG_ 3221225472 Obj0_LatitudeDistance "横向距离";
CM_ SG_ 3221225472 Obj0_LongitudeDistance "纵向距离";
CM_ SG_ 3221225472 Obj0_LatitudeSpeed "横向速度";
CM_ SG_ 3221225472 Obj0_LongitudeSpeed "纵向速度";
CM_ SG_ 3221225472 Obj0_ID "物体编号";
CM_ SG_ 3221225472 Obj0_Width "物体宽";
CM_ SG_ 3221225472 Obj0_HeadAngle "与车辆纵轴线连线角度";
CM_ SG_ 3221225472 Obj0_type "物体类型";
CM_ SG_ 3221225472 Obj0_Length "物体长";
CM_ SG_ 3221225472 Obj1_LatitudeDistance "横向距离";
CM_ SG_ 3221225472 Obj1_LongitudeDistance "纵向距离";
CM_ SG_ 3221225472 Obj1_LatitudeSpeed "横向速度";
CM_ SG_ 3221225472 Obj1_LongitudeSpeed "纵向速度";
CM_ SG_ 3221225472 Obj1_ID "物体编号";
CM_ SG_ 3221225472 Obj1_Width "物体宽";
CM_ SG_ 3221225472 Obj1_HeadAngle "与车辆纵轴线连线角度";
CM_ SG_ 3221225472 Obj1_type "物体类型";
CM_ SG_ 3221225472 Obj1_Length "物体长";
CM_ SG_ 3221225472 Obj2_LatitudeDistance "横向距离";
CM_ SG_ 3221225472 Obj2_LongitudeDistance "纵向距离";
CM_ SG_ 3221225472 Obj2_LatitudeSpeed "横向速度";
CM_ SG_ 3221225472 Obj2_LongitudeSpeed "纵向速度";
CM_ SG_ 3221225472 Obj2_ID "物体编号";
CM_ SG_ 3221225472 Obj2_Width "物体宽";
CM_ SG_ 3221225472 Obj2_HeadAngle "与车辆纵轴线连线角度";
CM_ SG_ 3221225472 Obj2_type "物体类型";
CM_ SG_ 3221225472 Obj2_Length "物体长";
CM_ SG_ 3221225472 Obj3_LatitudeDistance "横向距离";
CM_ SG_ 3221225472 Obj3_LongitudeDistance "纵向距离";
CM_ SG_ 3221225472 Obj3_LatitudeSpeed "横向速度";
CM_ SG_ 3221225472 Obj3_LongitudeSpeed "纵向速度";
CM_ SG_ 3221225472 Obj3_ID "物体编号";
CM_ SG_ 3221225472 Obj3_Width "物体宽";
CM_ SG_ 3221225472 Obj3_HeadAngle "与车辆纵轴线连线角度";
CM_ SG_ 3221225472 Obj3_type "物体类型";
CM_ SG_ 3221225472 Obj3_Length "物体长";
CM_ SG_ 3221225472 Obj4_LatitudeDistance "横向距离";
CM_ SG_ 3221225472 Obj4_LongitudeDistance "纵向距离";
CM_ SG_ 3221225472 Obj4_LatitudeSpeed "横向速度";
CM_ SG_ 3221225472 Obj4_LongitudeSpeed "纵向速度";
CM_ SG_ 3221225472 Obj4_ID "物体编号";
CM_ SG_ 3221225472 Obj4_Width "物体宽";
CM_ SG_ 3221225472 Obj4_HeadAngle "与车辆纵轴线连线角度";
CM_ SG_ 3221225472 Obj4_type "物体类型";
CM_ SG_ 3221225472 Obj4_Length "物体长";
CM_ SG_ 3221225472 Obj5_LatitudeDistance "横向距离";
CM_ SG_ 3221225472 Obj5_LongitudeDistance "纵向距离";
CM_ SG_ 3221225472 Obj5_LatitudeSpeed "横向速度";
CM_ SG_ 3221225472 Obj5_LongitudeSpeed "纵向速度";
CM_ SG_ 3221225472 Obj5_ID "物体编号";
CM_ SG_ 3221225472 Obj5_Width "物体宽";
CM_ SG_ 3221225472 Obj5_HeadAngle "与车辆纵轴线连线角度";
CM_ SG_ 3221225472 Obj5_type "物体类型";
CM_ SG_ 3221225472 Obj5_Length "物体长";
CM_ SG_ 3221225472 Obj6_LatitudeDistance "横向距离";
CM_ SG_ 3221225472 Obj6_LongitudeDistance "纵向距离";
CM_ SG_ 3221225472 Obj6_LatitudeSpeed "横向速度";
CM_ SG_ 3221225472 Obj6_LongitudeSpeed "纵向速度";
CM_ SG_ 3221225472 Obj6_ID "物体编号";
CM_ SG_ 3221225472 Obj6_Width "物体宽";
CM_ SG_ 3221225472 Obj6_HeadAngle "与车辆纵轴线连线角度";
CM_ SG_ 3221225472 Obj6_type "物体类型";
CM_ SG_ 3221225472 Obj6_Length "物体长";
CM_ SG_ 3221225472 Obj7_LatitudeDistance "横向距离";
CM_ SG_ 3221225472 Obj7_LongitudeDistance "纵向距离";
CM_ SG_ 3221225472 Obj7_LatitudeSpeed "横向速度";
CM_ SG_ 3221225472 Obj7_LongitudeSpeed "纵向速度";
CM_ SG_ 3221225472 Obj7_ID "物体编号";
CM_ SG_ 3221225472 Obj7_Width "物体宽";
CM_ SG_ 3221225472 Obj7_HeadAngle "与车辆纵轴线连线角度";
CM_ SG_ 3221225472 Obj7_type "物体类型";
CM_ SG_ 3221225472 Obj7_Length "物体长";
CM_ SG_ 3221225472 Obj8_LatitudeDistance "横向距离";
CM_ SG_ 3221225472 Obj8_LongitudeDistance "纵向距离";
CM_ SG_ 3221225472 Obj8_LatitudeSpeed "横向速度";
CM_ SG_ 3221225472 Obj8_LongitudeSpeed "纵向速度";
CM_ SG_ 3221225472 Obj8_ID "物体编号";
CM_ SG_ 3221225472 Obj8_Width "物体宽";
CM_ SG_ 3221225472 Obj8_HeadAngle "与车辆纵轴线连线角度";
CM_ SG_ 3221225472 Obj8_type "物体类型";
CM_ SG_ 3221225472 Obj8_Length "物体长";
CM_ SG_ 3221225472 Obj9_LatitudeDistance "横向距离";
CM_ SG_ 3221225472 Obj9_LongitudeDistance "纵向距离";
CM_ SG_ 3221225472 Obj9_LatitudeSpeed "横向速度";
CM_ SG_ 3221225472 Obj9_LongitudeSpeed "纵向速度";
CM_ SG_ 3221225472 Obj9_ID "物体编号";
CM_ SG_ 3221225472 Obj9_Width "物体宽";
CM_ SG_ 3221225472 Obj9_HeadAngle "与车辆纵轴线连线角度";
CM_ SG_ 3221225472 Obj9_type "物体类型";
CM_ SG_ 3221225472 Obj9_Length "物体长";
CM_ SG_ 3221225472 Obj10_LatitudeDistance "横向距离";
CM_ SG_ 3221225472 Obj10_LongitudeDistance "纵向距离";
CM_ SG_ 3221225472 Obj10_LatitudeSpeed "横向速度";
CM_ SG_ 3221225472 Obj10_LongitudeSpeed "纵向速度";
CM_ SG_ 3221225472 Obj10_ID "物体编号";
CM_ SG_ 3221225472 Obj10_Width "物体宽";
CM_ SG_ 3221225472 Obj10_HeadAngle "与车辆纵轴线连线角度";
CM_ SG_ 3221225472 Obj10_type "物体类型";
CM_ SG_ 3221225472 Obj10_Length "物体长";
CM_ SG_ 3221225472 Obj11_LatitudeDistance "横向距离";
CM_ SG_ 3221225472 Obj11_LongitudeDistance "纵向距离";
CM_ SG_ 3221225472 Obj11_LatitudeSpeed "横向速度";
CM_ SG_ 3221225472 Obj11_LongitudeSpeed "纵向速度";
CM_ SG_ 3221225472 Obj11_ID "物体编号";
CM_ SG_ 3221225472 Obj11_Width "物体宽";
CM_ SG_ 3221225472 Obj11_HeadAngle "与车辆纵轴线连线角度";
CM_ SG_ 3221225472 Obj11_type "物体类型";
CM_ SG_ 3221225472 Obj11_Length "物体长";
CM_ SG_ 3221225472 Obj12_LatitudeDistance "横向距离";
CM_ SG_ 3221225472 Obj12_LongitudeDistance "纵向距离";
CM_ SG_ 3221225472 Obj12_LatitudeSpeed "横向速度";
CM_ SG_ 3221225472 Obj12_LongitudeSpeed "纵向速度";
CM_ SG_ 3221225472 Obj12_ID "物体编号";
CM_ SG_ 3221225472 Obj12_Width "物体宽";
CM_ SG_ 3221225472 Obj12_HeadAngle "与车辆纵轴线连线角度";
CM_ SG_ 3221225472 Obj12_type "物体类型";
CM_ SG_ 3221225472 Obj12_Length "物体长";
CM_ SG_ 3221225472 Obj13_LatitudeDistance "横向距离";
CM_ SG_ 3221225472 Obj13_LongitudeDistance "纵向距离";
CM_ SG_ 3221225472 Obj13_LatitudeSpeed "横向速度";
CM_ SG_ 3221225472 Obj13_LongitudeSpeed "纵向速度";
CM_ SG_ 3221225472 Obj13_ID "物体编号";
CM_ SG_ 3221225472 Obj13_Width "物体宽";
CM_ SG_ 3221225472 Obj13_HeadAngle "与车辆纵轴线连线角度";
CM_ SG_ 3221225472 Obj13_type "物体类型";
CM_ SG_ 3221225472 Obj13_Length "物体长";
CM_ SG_ 3221225472 Obj14_LatitudeDistance "横向距离";
CM_ SG_ 3221225472 Obj14_LongitudeDistance "纵向距离";
CM_ SG_ 3221225472 Obj14_LatitudeSpeed "横向速度";
CM_ SG_ 3221225472 Obj14_LongitudeSpeed "纵向速度";
CM_ SG_ 3221225472 Obj14_ID "物体编号";
CM_ SG_ 3221225472 Obj14_Width "物体宽";
CM_ SG_ 3221225472 Obj14_HeadAngle "与车辆纵轴线连线角度";
CM_ SG_ 3221225472 Obj14_type "物体类型";
CM_ SG_ 3221225472 Obj14_Length "物体长";
CM_ SG_ 3221225472 Obj15_LatitudeDistance "横向距离";
CM_ SG_ 3221225472 Obj15_LongitudeDistance "纵向距离";
CM_ SG_ 3221225472 Obj15_LatitudeSpeed "横向速度";
CM_ SG_ 3221225472 Obj15_LongitudeSpeed "纵向速度";
CM_ SG_ 3221225472 Obj15_ID "物体编号";
CM_ SG_ 3221225472 Obj15_Width "物体宽";
CM_ SG_ 3221225472 Obj15_HeadAngle "与车辆纵轴线连线角度";
CM_ SG_ 3221225472 Obj15_type "物体类型";
CM_ SG_ 3221225472 Obj15_Length "物体长";
CM_ SG_ 3221225472 Obj16_LatitudeDistance "横向距离";
CM_ SG_ 3221225472 Obj16_LongitudeDistance "纵向距离";
CM_ SG_ 3221225472 Obj16_LatitudeSpeed "横向速度";
CM_ SG_ 3221225472 Obj16_LongitudeSpeed "纵向速度";
CM_ SG_ 3221225472 Obj16_ID "物体编号";
CM_ SG_ 3221225472 Obj16_Width "物体宽";
CM_ SG_ 3221225472 Obj16_HeadAngle "与车辆纵轴线连线角度";
CM_ SG_ 3221225472 Obj16_type "物体类型";
CM_ SG_ 3221225472 Obj16_Length "物体长";
CM_ SG_ 3221225472 Obj17_LatitudeDistance "横向距离";
CM_ SG_ 3221225472 Obj17_LongitudeDistance "纵向距离";
CM_ SG_ 3221225472 Obj17_LatitudeSpeed "横向速度";
CM_ SG_ 3221225472 Obj17_LongitudeSpeed "纵向速度";
CM_ SG_ 3221225472 Obj17_ID "物体编号";
CM_ SG_ 3221225472 Obj17_Width "物体宽";
CM_ SG_ 3221225472 Obj17_HeadAngle "与车辆纵轴线连线角度";
CM_ SG_ 3221225472 Obj17_type "物体类型";
CM_ SG_ 3221225472 Obj17_Length "物体长";
CM_ SG_ 3221225472 Obj18_LatitudeDistance "横向距离";
CM_ SG_ 3221225472 Obj18_LongitudeDistance "纵向距离";
CM_ SG_ 3221225472 Obj18_LatitudeSpeed "横向速度";
CM_ SG_ 3221225472 Obj18_LongitudeSpeed "纵向速度";
CM_ SG_ 3221225472 Obj18_ID "物体编号";
CM_ SG_ 3221225472 Obj18_Width "物体宽";
CM_ SG_ 3221225472 Obj18_HeadAngle "与车辆纵轴线连线角度";
CM_ SG_ 3221225472 Obj18_type "物体类型";
CM_ SG_ 3221225472 Obj18_Length "物体长";
CM_ SG_ 3221225472 Obj19_LatitudeDistance "横向距离";
CM_ SG_ 3221225472 Obj19_LongitudeDistance "纵向距离";
CM_ SG_ 3221225472 Obj19_LatitudeSpeed "横向速度";
CM_ SG_ 3221225472 Obj19_LongitudeSpeed "纵向速度";
CM_ SG_ 3221225472 Obj19_ID "物体编号";
CM_ SG_ 3221225472 Obj19_Width "物体宽";
CM_ SG_ 3221225472 Obj19_HeadAngle "与车辆纵轴线连线角度";
CM_ SG_ 3221225472 Obj19_type "物体类型";
CM_ SG_ 3221225472 Obj19_Length "物体长";
CM_ SG_ 3221225472 Obj20_LatitudeDistance "横向距离";
CM_ SG_ 3221225472 Obj20_LongitudeDistance "纵向距离";
CM_ SG_ 3221225472 Obj20_LatitudeSpeed "横向速度";
CM_ SG_ 3221225472 Obj20_LongitudeSpeed "纵向速度";
CM_ SG_ 3221225472 Obj20_ID "物体编号";
CM_ SG_ 3221225472 Obj20_Width "物体宽";
CM_ SG_ 3221225472 Obj20_HeadAngle "与车辆纵轴线连线角度";
CM_ SG_ 3221225472 Obj20_type "物体类型";
CM_ SG_ 3221225472 Obj20_Length "物体长";
CM_ SG_ 3221225472 Obj21_LatitudeDistance "横向距离";
CM_ SG_ 3221225472 Obj21_LongitudeDistance "纵向距离";
CM_ SG_ 3221225472 Obj21_LatitudeSpeed "横向速度";
CM_ SG_ 3221225472 Obj21_LongitudeSpeed "纵向速度";
CM_ SG_ 3221225472 Obj21_ID "物体编号";
CM_ SG_ 3221225472 Obj21_Width "物体宽";
CM_ SG_ 3221225472 Obj21_HeadAngle "与车辆纵轴线连线角度";
CM_ SG_ 3221225472 Obj21_type "物体类型";
CM_ SG_ 3221225472 Obj21_Length "物体长";
CM_ SG_ 3221225472 Obj22_LatitudeDistance "横向距离";
CM_ SG_ 3221225472 Obj22_LongitudeDistance "纵向距离";
CM_ SG_ 3221225472 Obj22_LatitudeSpeed "横向速度";
CM_ SG_ 3221225472 Obj22_LongitudeSpeed "纵向速度";
CM_ SG_ 3221225472 Obj22_ID "物体编号";
CM_ SG_ 3221225472 Obj22_Width "物体宽";
CM_ SG_ 3221225472 Obj22_HeadAngle "与车辆纵轴线连线角度";
CM_ SG_ 3221225472 Obj22_type "物体类型";
CM_ SG_ 3221225472 Obj22_Length "物体长";
CM_ SG_ 3221225472 Obj23_LatitudeDistance "横向距离";
CM_ SG_ 3221225472 Obj23_LongitudeDistance "纵向距离";
CM_ SG_ 3221225472 Obj23_LatitudeSpeed "横向速度";
CM_ SG_ 3221225472 Obj23_LongitudeSpeed "纵向速度";
CM_ SG_ 3221225472 Obj23_ID "物体编号";
CM_ SG_ 3221225472 Obj23_Width "物体宽";
CM_ SG_ 3221225472 Obj23_HeadAngle "与车辆纵轴线连线角度";
CM_ SG_ 3221225472 Obj23_type "物体类型";
CM_ SG_ 3221225472 Obj23_Length "物体长";
CM_ SG_ 3221225472 Obj24_LatitudeDistance "横向距离";
CM_ SG_ 3221225472 Obj24_LongitudeDistance "纵向距离";
CM_ SG_ 3221225472 Obj24_LatitudeSpeed "横向速度";
CM_ SG_ 3221225472 Obj24_LongitudeSpeed "纵向速度";
CM_ SG_ 3221225472 Obj24_ID "物体编号";
CM_ SG_ 3221225472 Obj24_Width "物体宽";
CM_ SG_ 3221225472 Obj24_HeadAngle "与车辆纵轴线连线角度";
CM_ SG_ 3221225472 Obj24_type "物体类型";
CM_ SG_ 3221225472 Obj24_Length "物体长";
CM_ SG_ 3221225472 Obj25_LatitudeDistance "横向距离";
CM_ SG_ 3221225472 Obj25_LongitudeDistance "纵向距离";
CM_ SG_ 3221225472 Obj25_LatitudeSpeed "横向速度";
CM_ SG_ 3221225472 Obj25_LongitudeSpeed "纵向速度";
CM_ SG_ 3221225472 Obj25_ID "物体编号";
CM_ SG_ 3221225472 Obj25_Width "物体宽";
CM_ SG_ 3221225472 Obj25_HeadAngle "与车辆纵轴线连线角度";
CM_ SG_ 3221225472 Obj25_type "物体类型";
CM_ SG_ 3221225472 Obj25_Length "物体长";
CM_ SG_ 3221225472 Obj26_LatitudeDistance "横向距离";
CM_ SG_ 3221225472 Obj26_LongitudeDistance "纵向距离";
CM_ SG_ 3221225472 Obj26_LatitudeSpeed "横向速度";
CM_ SG_ 3221225472 Obj26_LongitudeSpeed "纵向速度";
CM_ SG_ 3221225472 Obj26_ID "物体编号";
CM_ SG_ 3221225472 Obj26_Width "物体宽";
CM_ SG_ 3221225472 Obj26_HeadAngle "与车辆纵轴线连线角度";
CM_ SG_ 3221225472 Obj26_type "物体类型";
CM_ SG_ 3221225472 Obj26_Length "物体长";
CM_ SG_ 3221225472 Obj27_LatitudeDistance "横向距离";
CM_ SG_ 3221225472 Obj27_LongitudeDistance "纵向距离";
CM_ SG_ 3221225472 Obj27_LatitudeSpeed "横向速度";
CM_ SG_ 3221225472 Obj27_LongitudeSpeed "纵向速度";
CM_ SG_ 3221225472 Obj27_ID "物体编号";
CM_ SG_ 3221225472 Obj27_Width "物体宽";
CM_ SG_ 3221225472 Obj27_HeadAngle "与车辆纵轴线连线角度";
CM_ SG_ 3221225472 Obj27_type "物体类型";
CM_ SG_ 3221225472 Obj27_Length "物体长";
CM_ SG_ 3221225472 Obj28_LatitudeDistance "横向距离";
CM_ SG_ 3221225472 Obj28_LongitudeDistance "纵向距离";
CM_ SG_ 3221225472 Obj28_LatitudeSpeed "横向速度";
CM_ SG_ 3221225472 Obj28_LongitudeSpeed "纵向速度";
CM_ SG_ 3221225472 Obj28_ID "物体编号";
CM_ SG_ 3221225472 Obj28_Width "物体宽";
CM_ SG_ 3221225472 Obj28_HeadAngle "与车辆纵轴线连线角度";
CM_ SG_ 3221225472 Obj28_type "物体类型";
CM_ SG_ 3221225472 Obj28_Length "物体长";
CM_ SG_ 3221225472 Obj29_LatitudeDistance "横向距离";
CM_ SG_ 3221225472 Obj29_LongitudeDistance "纵向距离";
CM_ SG_ 3221225472 Obj29_LatitudeSpeed "横向速度";
CM_ SG_ 3221225472 Obj29_LongitudeSpeed "纵向速度";
CM_ SG_ 3221225472 Obj29_ID "物体编号";
CM_ SG_ 3221225472 Obj29_Width "物体宽";
CM_ SG_ 3221225472 Obj29_HeadAngle "与车辆纵轴线连线角度";
CM_ SG_ 3221225472 Obj29_type "物体类型";
CM_ SG_ 3221225472 Obj29_Length "物体长";
CM_ SG_ 3221225472 Obj30_LatitudeDistance "横向距离";
CM_ SG_ 3221225472 Obj30_LongitudeDistance "纵向距离";
CM_ SG_ 3221225472 Obj30_LatitudeSpeed "横向速度";
CM_ SG_ 3221225472 Obj30_LongitudeSpeed "纵向速度";
CM_ SG_ 3221225472 Obj30_ID "物体编号";
CM_ SG_ 3221225472 Obj30_Width "物体宽";
CM_ SG_ 3221225472 Obj30_HeadAngle "与车辆纵轴线连线角度";
CM_ SG_ 3221225472 Obj30_type "物体类型";
CM_ SG_ 3221225472 Obj30_Length "物体长";
CM_ SG_ 3221225472 Obj31_LatitudeDistance "横向距离";
CM_ SG_ 3221225472 Obj31_LongitudeDistance "纵向距离";
CM_ SG_ 3221225472 Obj31_LatitudeSpeed "横向速度";
CM_ SG_ 3221225472 Obj31_LongitudeSpeed "纵向速度";
CM_ SG_ 3221225472 Obj31_ID "物体编号";
CM_ SG_ 3221225472 Obj31_Width "物体宽";
CM_ SG_ 3221225472 Obj31_HeadAngle "与车辆纵轴线连线角度";
CM_ SG_ 3221225472 Obj31_type "物体类型";
CM_ SG_ 3221225472 Obj31_Length "物体长";
CM_ SG_ 3221225472 GPS_PDOP "位置的精度强弱度（精度、纬度和高度三者误差的平方和开根号）";
CM_ SG_ 3221225472 GPS_HDOP "水平坐标的精度强弱度（纬度和精度误差的平方和开根号）";
CM_ SG_ 3221225472 GPS_VDOP "高度的误差值";
CM_ SG_ 3221225472 GPS_GDOP "dilution of precision解析精度（精度、纬度、高度、时间误差的平方和开根号）";
CM_ SG_ 3221225472 GPS_HeadingAngle "运动方向";
CM_ SG_ 3221225472 GPS_LocatHeight "高度";
CM_ SG_ 3221225472 GPS_Time "时间";
CM_ SG_ 3221225472 GPS_Latitude "经度";
CM_ SG_ 3221225472 GPS_Lontitude "纬度";
CM_ SG_ 3221225472 GPS_UTC_sec "UTC时间（秒）";
CM_ SG_ 3221225472 GPS_UTC_week "UTC时间（周）";
CM_ SG_ 3221225472 INS_A_Y "Y方向加速度计感应的加速度";
CM_ SG_ 3221225472 INS_A_X "X方向加速度计感应的加速度";
CM_ SG_ 3221225472 INS_A_Z "Z方向加速度计感应的加速度";
CM_ SG_ 3221225472 GPS_flag_pos "GPS的差分状态";
CM_ SG_ 3221225472 GPS_flag_heading "GPS航向差分状态";
CM_ SG_ 3221225472 GPS_age "GPS差分差龄";
CM_ SG_ 3221225472 car_statue "车辆状态";
CM_ SG_ 3221225472 INS_statue "惯导状态";
CM_ SG_ 3221225472 GPS_numsv "卫星数";
CM_ SG_ 3221225472 INS_GYRO_Y "陀螺仪监测的Y轴旋转速度";
CM_ SG_ 3221225472 INS_GYRO_Z "陀螺仪监测的Z轴旋转速度";
CM_ SG_ 3221225472 INS_GYRO_X "陀螺仪监测的X轴旋转速度";
CM_ SG_ 3221225472 INS_RollAngle "横摆角";
CM_ SG_ 3221225472 INS_HeadingAngle "偏航角";
CM_ SG_ 3221225472 INS_PitchAngle "俯仰角";
CM_ SG_ 3221225472 INS_LocatHeight "高度";
CM_ SG_ 3221225472 INS_Time "时间";
CM_ SG_ 3221225472 INS_Latitude "经度";
CM_ SG_ 3221225472 INS_Longitude "纬度";
CM_ SG_ 3221225472 INS_NorthSpd "北东地速度—北";
CM_ SG_ 3221225472 INS_ToGroundSpd "北东地速度—地";
CM_ SG_ 3221225472 INS_EastSpd "北东地速度—东";
CM_ SG_ 3221225472 INS_Std_Lon "惯导精度估计精度";
CM_ SG_ 3221225472 INS_Std_Height "高度估计精度";
CM_ SG_ 3221225472 INS_Std_Lat "惯导纬度估计精度";
CM_ SG_ 3221225472 IPC_CPSLaneNumber "车道号";
CM_ SG_ 3221225472 IPC_CPSDirectionIndication "方向指示";
CM_ SG_ 3221225472 IPC_CPSCameraUsed "找CPS哪个摄像头在工作";
CM_ SG_ 3221225472 IPC_BayNumberCameraUsed "找备位号哪个摄像头在工作";
CM_ SG_ 3221225472 IPC_BayNumber "备位号";
CM_ SG_ 3221225472 IPC_BayRemainingDistanceX "剩余距离—X方向";
CM_ SG_ 3221225472 IPC_BayRemainingDistanceY "剩余距离—Y方向";
CM_ SG_ 3221225472 IPC_CPSDisplayNumber "数字显示";
CM_ SG_ 3221225472 IPC_ContainerSizeAndPosition "集装箱大小及位置";
CM_ SG_ 3221225472 IPC_CPSRightCameraStatus "CPS右摄像头状态";
CM_ SG_ 3221225472 IPC_BayNumLeftCameraStatus "备位左摄像头状态";
CM_ SG_ 3221225472 IPC_BayNumRightCameraStatus "备位右摄像头状态";
CM_ SG_ 3221225472 IPC_HangerCameraStatus "吊钩&集装箱摄像头状态";
CM_ SG_ 3221225472 IPC_HangerStatus "吊爪状态";
CM_ SG_ 3221225472 IPC_CPSLeftCameraStatus "CPS左摄像头状态";
CM_ SG_ 3221225472 S32V_ToADU_Reserved1 "预留，16个bit";
CM_ SG_ 3221225472 S32V_ToADU_Reserved2 "预留，16个bit";
CM_ SG_ 3221225472 S32V_ToADU_Reserved3 "预留，16个bit";
CM_ SG_ 3221225472 S32V_ToADU_Reserved4 "预留，16个bit";
CM_ SG_ 3221225472 S32V_ToADU_Reserved5 "预留，16个bit";
CM_ SG_ 3221225472 S32V_ToADU_Reserved6 "预留，16个bit";
CM_ SG_ 3221225472 S32V_ToADU_Reserved7 "预留，16个bit";
CM_ SG_ 3221225472 S32V_ToADU_Reserved8 "预留，16个bit";
CM_ SG_ 3221225472 S32V_ToADU_Reserved9 "预留，16个bit";
CM_ SG_ 3221225472 S32V_ToADU_Reserved10 "预留，16个bit";
CM_ SG_ 3221225472 S32V_ToADU_Reserved11 "预留，16个bit";
CM_ SG_ 3221225472 S32V_ToADU_Reserved12 "预留，16个bit";
CM_ SG_ 3221225472 S32V_ToADU_Reserved13 "预留，8个bit";
CM_ SG_ 3221225472 S32V_ToADU_Reserved15 "预留，8个bit";
CM_ SG_ 3221225472 S32V_ToADU_Reserved16 "预留，8个bit";
CM_ SG_ 3221225472 S32V_ToADU_Reserved17 "预留，8个bit";
CM_ SG_ 3221225472 S32V_ToADU_Reserved18 "预留，8个bit";
CM_ SG_ 3221225472 S32V_ToADU_Reserved19 "预留，8个bit";
CM_ SG_ 3221225472 S32V_ToADU_Reserved20 "预留，8个bit";
CM_ SG_ 3221225472 S32V_ToADU_Reserved14 "预留，8个bit";
CM_ SG_ 3221225472 S32V_ToADU_Reserved21 "预留，8个bit";
CM_ SG_ 3221225472 S32V_ToADU_Reserved23 "预留，8个bit";
CM_ SG_ 3221225472 S32V_ToADU_Reserved24 "预留，8个bit";
CM_ SG_ 3221225472 S32V_ToADU_Reserved25 "预留，8个bit";
CM_ SG_ 3221225472 S32V_ToADU_Reserved26 "预留，8个bit";
CM_ SG_ 3221225472 S32V_ToADU_Reserved27 "预留，8个bit";
CM_ SG_ 3221225472 S32V_ToADU_Reserved28 "预留，8个bit";
CM_ SG_ 3221225472 S32V_ToADU_Reserved22 "预留，8个bit";
CM_ SG_ 3221225472 adu_ToS32V_Reserved1 "预留，16个bit";
CM_ SG_ 3221225472 adu_ToS32V_Reserved2 "预留，16个bit";
CM_ SG_ 3221225472 adu_ToS32V_Reserved3 "预留，16个bit";
CM_ SG_ 3221225472 adu_ToS32V_Reserved4 "预留，16个bit";
CM_ SG_ 3221225472 adu_ToS32V_Reserved5 "预留，16个bit";
CM_ SG_ 3221225472 adu_ToS32V_Reserved6 "预留，16个bit";
CM_ SG_ 3221225472 adu_ToS32V_Reserved7 "预留，16个bit";
CM_ SG_ 3221225472 adu_ToS32V_Reserved8 "预留，16个bit";
CM_ SG_ 3221225472 adu_ToS32V_Reserved9 "预留，16个bit";
CM_ SG_ 3221225472 adu_ToS32V_Reserved10 "预留，16个bit";
CM_ SG_ 3221225472 adu_ToS32V_Reserved11 "预留，16个bit";
CM_ SG_ 3221225472 adu_ToS32V_Reserved12 "预留，16个bit";
CM_ SG_ 3221225472 adu_ToS32V_Reserved13 "预留，8个bit";
CM_ SG_ 3221225472 adu_ToS32V_Reserved15 "预留，8个bit";
CM_ SG_ 3221225472 adu_ToS32V_Reserved16 "预留，8个bit";
CM_ SG_ 3221225472 adu_ToS32V_Reserved17 "预留，8个bit";
CM_ SG_ 3221225472 adu_ToS32V_Reserved18 "预留，8个bit";
CM_ SG_ 3221225472 adu_ToS32V_Reserved19 "预留，8个bit";
CM_ SG_ 3221225472 adu_ToS32V_Reserved20 "预留，8个bit";
CM_ SG_ 3221225472 adu_ToS32V_Reserved14 "预留，8个bit";
CM_ SG_ 3221225472 adu_ToS32V_Reserved21 "预留，8个bit";
CM_ SG_ 3221225472 adu_ToS32V_Reserved23 "预留，8个bit";
CM_ SG_ 3221225472 adu_ToS32V_Reserved24 "预留，8个bit";
CM_ SG_ 3221225472 adu_ToS32V_Reserved25 "预留，8个bit";
CM_ SG_ 3221225472 adu_ToS32V_Reserved26 "预留，8个bit";
CM_ SG_ 3221225472 adu_ToS32V_Reserved27 "预留，8个bit";
CM_ SG_ 3221225472 adu_ToS32V_Reserved28 "预留，8个bit";
CM_ SG_ 3221225472 adu_ToS32V_Reserved22 "预留，8个bit";
CM_ SG_ 1793 FRDistance1 "freespace点距离";
CM_ SG_ 1793 FRDistance2 "freespace点距离";
CM_ SG_ 1793 FRDistance3 "freespace点距离";
CM_ SG_ 1793 FRDistance4 "freespace点距离";
CM_ SG_ 1793 FRDistance5 "freespace点距离";
CM_ SG_ 1793 FRDistance6 "freespace点距离";
CM_ SG_ 1793 Counter_701 "计数校验";
CM_ SG_ 1794 FRDistance7 "freespace点距离";
CM_ SG_ 1794 FRDistance8 "freespace点距离";
CM_ SG_ 1794 FRDistance9 "freespace点距离";
CM_ SG_ 1794 FRDistance10 "freespace点距离";
CM_ SG_ 1794 FRDistance11 "freespace点距离";
CM_ SG_ 1794 FRDistance12 "freespace点距离";
CM_ SG_ 1794 Counter_702 "计数校验";
CM_ SG_ 1795 FRDistance13 "freespace点距离";
CM_ SG_ 1795 FRDistance14 "freespace点距离";
CM_ SG_ 1795 FRDistance15 "freespace点距离";
CM_ SG_ 1795 FRDistance16 "freespace点距离";
CM_ SG_ 1795 FRDistance17 "freespace点距离";
CM_ SG_ 1795 FRDistance18 "freespace点距离";
CM_ SG_ 1795 Counter_703 "计数校验";
CM_ SG_ 1796 FRDistance19 "freespace点距离";
CM_ SG_ 1796 FRDistance20 "freespace点距离";
CM_ SG_ 1796 FRDistance21 "freespace点距离";
CM_ SG_ 1796 FRDistance22 "freespace点距离";
CM_ SG_ 1796 FRDistance23 "freespace点距离";
CM_ SG_ 1796 FRDistance24 "freespace点距离";
CM_ SG_ 1796 Counter_704 "计数校验";
CM_ SG_ 1797 FRDistance25 "freespace点距离";
CM_ SG_ 1797 FRDistance26 "freespace点距离";
CM_ SG_ 1797 FRDistance27 "freespace点距离";
CM_ SG_ 1797 FRDistance28 "freespace点距离";
CM_ SG_ 1797 FRDistance29 "freespace点距离";
CM_ SG_ 1797 FRDistance30 "freespace点距离";
CM_ SG_ 1797 Counter_705 "计数校验";
CM_ SG_ 1798 FRDistance31 "freespace点距离";
CM_ SG_ 1798 FRDistance32 "freespace点距离";
CM_ SG_ 1798 FRDistance33 "freespace点距离";
CM_ SG_ 1798 FRDistance34 "freespace点距离";
CM_ SG_ 1798 FRDistance35 "freespace点距离";
CM_ SG_ 1798 FRDistance36 "freespace点距离";
CM_ SG_ 1798 Counter_706 "计数校验";
CM_ SG_ 1799 FRDistance37 "freespace点距离";
CM_ SG_ 1799 FRDistance38 "freespace点距离";
CM_ SG_ 1799 FRDistance39 "freespace点距离";
CM_ SG_ 1799 FRDistance40 "freespace点距离";
CM_ SG_ 1799 FRDistance41 "freespace点距离";
CM_ SG_ 1799 FRDistance42 "freespace点距离";
CM_ SG_ 1799 Counter_707 "计数校验";
CM_ SG_ 1800 FRDistance43 "freespace点距离";
CM_ SG_ 1800 FRDistance44 "freespace点距离";
CM_ SG_ 1800 FRDistance45 "freespace点距离";
CM_ SG_ 1800 FRDistance46 "freespace点距离";
CM_ SG_ 1800 FRDistance47 "freespace点距离";
CM_ SG_ 1800 FRDistance48 "freespace点距离";
CM_ SG_ 1800 Counter_708 "计数校验";
CM_ SG_ 1801 FRDistance49 "freespace点距离";
CM_ SG_ 1801 FRDistance50 "freespace点距离";
CM_ SG_ 1801 FRDistance51 "freespace点距离";
CM_ SG_ 1801 FRDistance52 "freespace点距离";
CM_ SG_ 1801 FRDistance53 "freespace点距离";
CM_ SG_ 1801 FRDistance54 "freespace点距离";
CM_ SG_ 1801 Counter_709 "计数校验";
CM_ SG_ 1802 FRDistance55 "freespace点距离";
CM_ SG_ 1802 FRDistance56 "freespace点距离";
CM_ SG_ 1802 FRDistance57 "freespace点距离";
CM_ SG_ 1802 FRDistance58 "freespace点距离";
CM_ SG_ 1802 FRDistance59 "freespace点距离";
CM_ SG_ 1802 FRDistance60 "freespace点距离";
CM_ SG_ 1802 Counter_70A "计数校验";
CM_ SG_ 1803 FRDistance61 "freespace点距离";
CM_ SG_ 1803 FRDistance62 "freespace点距离";
CM_ SG_ 1803 FRDistance63 "freespace点距离";
CM_ SG_ 1803 FRDistance64 "freespace点距离";
CM_ SG_ 1803 FRDistance65 "freespace点距离";
CM_ SG_ 1803 FRDistance66 "freespace点距离";
CM_ SG_ 1803 Counter_70B "计数校验";
CM_ SG_ 1804 FRDistance67 "freespace点距离";
CM_ SG_ 1804 FRDistance68 "freespace点距离";
CM_ SG_ 1804 FRDistance69 "freespace点距离";
CM_ SG_ 1804 FRDistance70 "freespace点距离";
CM_ SG_ 1804 FRDistance71 "freespace点距离";
CM_ SG_ 1804 FRDistance72 "freespace点距离";
CM_ SG_ 1804 Counter_70C "计数校验";
CM_ SG_ 1805 FRDistance73 "freespace点距离";
CM_ SG_ 1805 FRDistance74 "freespace点距离";
CM_ SG_ 1805 FRDistance75 "freespace点距离";
CM_ SG_ 1805 FRDistance76 "freespace点距离";
CM_ SG_ 1805 FRDistance77 "freespace点距离";
CM_ SG_ 1805 FRDistance78 "freespace点距离";
CM_ SG_ 1805 Counter_70D "计数校验";
CM_ SG_ 1806 FRDistance79 "freespace点距离";
CM_ SG_ 1806 FRDistance80 "freespace点距离";
CM_ SG_ 1806 FRDistance81 "freespace点距离";
CM_ SG_ 1806 FRDistance82 "freespace点距离";
CM_ SG_ 1806 FRDistance83 "freespace点距离";
CM_ SG_ 1806 FRDistance84 "freespace点距离";
CM_ SG_ 1806 Counter_70E "计数校验";
CM_ SG_ 1807 FRDistance85 "freespace点距离";
CM_ SG_ 1807 FRDistance86 "freespace点距离";
CM_ SG_ 1807 FRDistance87 "freespace点距离";
CM_ SG_ 1807 FRDistance88 "freespace点距离";
CM_ SG_ 1807 FRDistance89 "freespace点距离";
CM_ SG_ 1807 FRDistance90 "freespace点距离";
CM_ SG_ 1807 Counter_70F "计数校验";
CM_ SG_ 1808 FRDistance91 "freespace点距离";
CM_ SG_ 1808 FRDistance92 "freespace点距离";
CM_ SG_ 1808 FRDistance93 "freespace点距离";
CM_ SG_ 1808 FRDistance94 "freespace点距离";
CM_ SG_ 1808 FRDistance95 "freespace点距离";
CM_ SG_ 1808 FRDistance96 "freespace点距离";
CM_ SG_ 1808 Counter_710 "计数校验";
CM_ SG_ 1809 FRDistance97 "freespace点距离";
CM_ SG_ 1809 FRDistance98 "freespace点距离";
CM_ SG_ 1809 FRDistance99 "freespace点距离";
CM_ SG_ 1809 FRDistance100 "freespace点距离";
CM_ SG_ 1809 FRDistance101 "freespace点距离";
CM_ SG_ 1809 FRDistance102 "freespace点距离";
CM_ SG_ 1809 Counter_711 "计数校验";
CM_ SG_ 1810 FRDistance103 "freespace点距离";
CM_ SG_ 1810 FRDistance104 "freespace点距离";
CM_ SG_ 1810 FRDistance105 "freespace点距离";
CM_ SG_ 1810 FRDistance106 "freespace点距离";
CM_ SG_ 1810 FRDistance107 "freespace点距离";
CM_ SG_ 1810 FRDistance108 "freespace点距离";
CM_ SG_ 1810 Counter_712 "计数校验";
CM_ SG_ 1811 FRDistance109 "freespace点距离";
CM_ SG_ 1811 FRDistance110 "freespace点距离";
CM_ SG_ 1811 FRDistance111 "freespace点距离";
CM_ SG_ 1811 FRDistance112 "freespace点距离";
CM_ SG_ 1811 FRDistance113 "freespace点距离";
CM_ SG_ 1811 FRDistance114 "freespace点距离";
CM_ SG_ 1811 Counter_713 "计数校验";
CM_ SG_ 1812 FRDistance115 "freespace点距离";
CM_ SG_ 1812 FRDistance116 "freespace点距离";
CM_ SG_ 1812 FRDistance117 "freespace点距离";
CM_ SG_ 1812 FRDistance118 "freespace点距离";
CM_ SG_ 1812 FRDistance119 "freespace点距离";
CM_ SG_ 1812 FRDistance120 "freespace点距离";
CM_ SG_ 1812 Counter_714 "计数校验";
CM_ SG_ 1813 FRDistance121 "freespace点距离";
CM_ SG_ 1813 FRDistance122 "freespace点距离";
CM_ SG_ 1813 FRDistance123 "freespace点距离";
CM_ SG_ 1813 FRDistance124 "freespace点距离";
CM_ SG_ 1813 FRDistance125 "freespace点距离";
CM_ SG_ 1813 FRDistance126 "freespace点距离";
CM_ SG_ 1813 Counter_715 "计数校验";
CM_ SG_ 1814 FRDistance127 "freespace点距离";
CM_ SG_ 1814 FRDistance128 "freespace点距离";
CM_ SG_ 1814 FRDistance129 "freespace点距离";
CM_ SG_ 1814 FRDistance130 "freespace点距离";
CM_ SG_ 1814 FRDistance131 "freespace点距离";
CM_ SG_ 1814 FRDistance132 "freespace点距离";
CM_ SG_ 1814 Counter_716 "计数校验";
CM_ SG_ 1815 FRDistance133 "freespace点距离";
CM_ SG_ 1815 FRDistance134 "freespace点距离";
CM_ SG_ 1815 FRDistance135 "freespace点距离";
CM_ SG_ 1815 FRDistance136 "freespace点距离";
CM_ SG_ 1815 FRDistance137 "freespace点距离";
CM_ SG_ 1815 FRDistance138 "freespace点距离";
CM_ SG_ 1815 Counter_717 "计数校验";
CM_ SG_ 1816 FRDistance139 "freespace点距离";
CM_ SG_ 1816 FRDistance140 "freespace点距离";
CM_ SG_ 1816 FRDistance141 "freespace点距离";
CM_ SG_ 1816 FRDistance142 "freespace点距离";
CM_ SG_ 1816 FRDistance143 "freespace点距离";
CM_ SG_ 1816 FRDistance144 "freespace点距离";
CM_ SG_ 1816 Counter_718 "计数校验";
CM_ SG_ 1817 FRDistance145 "freespace点距离";
CM_ SG_ 1817 FRDistance146 "freespace点距离";
CM_ SG_ 1817 FRDistance147 "freespace点距离";
CM_ SG_ 1817 FRDistance148 "freespace点距离";
CM_ SG_ 1817 FRDistance149 "freespace点距离";
CM_ SG_ 1817 FRDistance150 "freespace点距离";
CM_ SG_ 1817 Counter_719 "计数校验";
CM_ SG_ 1818 FRDistance151 "freespace点距离";
CM_ SG_ 1818 FRDistance152 "freespace点距离";
CM_ SG_ 1818 FRDistance153 "freespace点距离";
CM_ SG_ 1818 FRDistance154 "freespace点距离";
CM_ SG_ 1818 FRDistance155 "freespace点距离";
CM_ SG_ 1818 FRDistance156 "freespace点距离";
CM_ SG_ 1818 Counter_71A "计数校验";
CM_ SG_ 1819 FRDistance157 "freespace点距离";
CM_ SG_ 1819 FRDistance158 "freespace点距离";
CM_ SG_ 1819 FRDistance159 "freespace点距离";
CM_ SG_ 1819 FRDistance160 "freespace点距离";
CM_ SG_ 1819 FRDistance161 "freespace点距离";
CM_ SG_ 1819 FRDistance162 "freespace点距离";
CM_ SG_ 1819 Counter_71B "计数校验";
CM_ SG_ 1820 FRDistance163 "freespace点距离";
CM_ SG_ 1820 FRDistance164 "freespace点距离";
CM_ SG_ 1820 FRDistance165 "freespace点距离";
CM_ SG_ 1820 FRDistance166 "freespace点距离";
CM_ SG_ 1820 FRDistance167 "freespace点距离";
CM_ SG_ 1820 FRDistance168 "freespace点距离";
CM_ SG_ 1820 Counter_71C "计数校验";
CM_ SG_ 1821 FRDistance169 "freespace点距离";
CM_ SG_ 1821 FRDistance170 "freespace点距离";
CM_ SG_ 1821 FRDistance171 "freespace点距离";
CM_ SG_ 1821 FRDistance172 "freespace点距离";
CM_ SG_ 1821 FRDistance173 "freespace点距离";
CM_ SG_ 1821 FRDistance174 "freespace点距离";
CM_ SG_ 1821 Counter_71D "计数校验";
CM_ SG_ 1822 FRDistance175 "freespace点距离";
CM_ SG_ 1822 FRDistance176 "freespace点距离";
CM_ SG_ 1822 FRDistance177 "freespace点距离";
CM_ SG_ 1822 FRDistance178 "freespace点距离";
CM_ SG_ 1822 FRDistance179 "freespace点距离";
CM_ SG_ 1822 FRDistance180 "freespace点距离";
CM_ SG_ 1822 Counter_71E "计数校验";
CM_ SG_ 1823 FRDistance181 "freespace点距离";
CM_ SG_ 1823 FRDistance182 "freespace点距离";
CM_ SG_ 1823 FRDistance183 "freespace点距离";
CM_ SG_ 1823 FRDistance184 "freespace点距离";
CM_ SG_ 1823 FRDistance185 "freespace点距离";
CM_ SG_ 1823 FRDistance186 "freespace点距离";
CM_ SG_ 1823 Counter_71F "计数校验";
CM_ SG_ 1824 FRDistance187 "freespace点距离";
CM_ SG_ 1824 FRDistance188 "freespace点距离";
CM_ SG_ 1824 FRDistance189 "freespace点距离";
CM_ SG_ 1824 FRDistance190 "freespace点距离";
CM_ SG_ 1824 FRDistance191 "freespace点距离";
CM_ SG_ 1824 FRDistance192 "freespace点距离";
CM_ SG_ 1824 Counter_720 "计数校验";
CM_ SG_ 1825 FRDistance193 "freespace点距离";
CM_ SG_ 1825 FRDistance194 "freespace点距离";
CM_ SG_ 1825 FRDistance195 "freespace点距离";
CM_ SG_ 1825 FRDistance196 "freespace点距离";
CM_ SG_ 1825 FRDistance197 "freespace点距离";
CM_ SG_ 1825 FRDistance198 "freespace点距离";
CM_ SG_ 1825 Counter_721 "计数校验";
CM_ SG_ 1826 FRDistance199 "freespace点距离";
CM_ SG_ 1826 FRDistance200 "freespace点距离";
CM_ SG_ 1826 FRDistance201 "freespace点距离";
CM_ SG_ 1826 FRDistance202 "freespace点距离";
CM_ SG_ 1826 FRDistance203 "freespace点距离";
CM_ SG_ 1826 FRDistance204 "freespace点距离";
CM_ SG_ 1826 Counter_722 "计数校验";
CM_ SG_ 1827 FRDistance205 "freespace点距离";
CM_ SG_ 1827 FRDistance206 "freespace点距离";
CM_ SG_ 1827 FRDistance207 "freespace点距离";
CM_ SG_ 1827 FRDistance208 "freespace点距离";
CM_ SG_ 1827 FRDistance209 "freespace点距离";
CM_ SG_ 1827 FRDistance210 "freespace点距离";
CM_ SG_ 1827 Counter_723 "计数校验";
CM_ SG_ 1828 FRDistance211 "freespace点距离";
CM_ SG_ 1828 FRDistance212 "freespace点距离";
CM_ SG_ 1828 FRDistance213 "freespace点距离";
CM_ SG_ 1828 FRDistance214 "freespace点距离";
CM_ SG_ 1828 FRDistance215 "freespace点距离";
CM_ SG_ 1828 FRDistance216 "freespace点距离";
CM_ SG_ 1828 Counter_724 "计数校验";
CM_ SG_ 1829 FRDistance217 "freespace点距离";
CM_ SG_ 1829 FRDistance218 "freespace点距离";
CM_ SG_ 1829 FRDistance219 "freespace点距离";
CM_ SG_ 1829 FRDistance220 "freespace点距离";
CM_ SG_ 1829 FRDistance221 "freespace点距离";
CM_ SG_ 1829 FRDistance222 "freespace点距离";
CM_ SG_ 1829 Counter_725 "计数校验";
CM_ SG_ 1830 FRDistance223 "freespace点距离";
CM_ SG_ 1830 FRDistance224 "freespace点距离";
CM_ SG_ 1830 FRDistance225 "freespace点距离";
CM_ SG_ 1830 FRDistance226 "freespace点距离";
CM_ SG_ 1830 FRDistance227 "freespace点距离";
CM_ SG_ 1830 FRDistance228 "freespace点距离";
CM_ SG_ 1830 Counter_726 "计数校验";
CM_ SG_ 1831 FRDistance229 "freespace点距离";
CM_ SG_ 1831 FRDistance230 "freespace点距离";
CM_ SG_ 1831 FRDistance231 "freespace点距离";
CM_ SG_ 1831 FRDistance232 "freespace点距离";
CM_ SG_ 1831 FRDistance233 "freespace点距离";
CM_ SG_ 1831 FRDistance234 "freespace点距离";
CM_ SG_ 1831 Counter_727 "计数校验";
CM_ SG_ 1832 FRDistance235 "freespace点距离";
CM_ SG_ 1832 FRDistance236 "freespace点距离";
CM_ SG_ 1832 FRDistance237 "freespace点距离";
CM_ SG_ 1832 FRDistance238 "freespace点距离";
CM_ SG_ 1832 FRDistance239 "freespace点距离";
CM_ SG_ 1832 FRDistance240 "freespace点距离";
CM_ SG_ 1832 Counter_728 "计数校验";
CM_ SG_ 1833 FRDistance241 "freespace点距离";
CM_ SG_ 1833 FRDistance242 "freespace点距离";
CM_ SG_ 1833 FRDistance243 "freespace点距离";
CM_ SG_ 1833 FRDistance244 "freespace点距离";
CM_ SG_ 1833 FRDistance245 "freespace点距离";
CM_ SG_ 1833 FRDistance246 "freespace点距离";
CM_ SG_ 1833 Counter_729 "计数校验";
CM_ SG_ 1834 FRDistance247 "freespace点距离";
CM_ SG_ 1834 FRDistance248 "freespace点距离";
CM_ SG_ 1834 FRDistance249 "freespace点距离";
CM_ SG_ 1834 FRDistance250 "freespace点距离";
CM_ SG_ 1834 FRDistance251 "freespace点距离";
CM_ SG_ 1834 FRDistance252 "freespace点距离";
CM_ SG_ 1834 Counter_72A "计数校验";
CM_ SG_ 1835 FRDistance253 "freespace点距离";
CM_ SG_ 1835 FRDistance254 "freespace点距离";
CM_ SG_ 1835 FRDistance255 "freespace点距离";
CM_ SG_ 1835 FRDistance256 "freespace点距离";
CM_ SG_ 1835 FRDistance257 "freespace点距离";
CM_ SG_ 1835 FRDistance258 "freespace点距离";
CM_ SG_ 1835 Counter_72B "计数校验";
CM_ SG_ 1836 FRDistance259 "freespace点距离";
CM_ SG_ 1836 FRDistance260 "freespace点距离";
CM_ SG_ 1836 FRDistance261 "freespace点距离";
CM_ SG_ 1836 FRDistance262 "freespace点距离";
CM_ SG_ 1836 FRDistance263 "freespace点距离";
CM_ SG_ 1836 FRDistance264 "freespace点距离";
CM_ SG_ 1836 Counter_72C "计数校验";
CM_ SG_ 1837 FRDistance265 "freespace点距离";
CM_ SG_ 1837 FRDistance266 "freespace点距离";
CM_ SG_ 1837 FRDistance267 "freespace点距离";
CM_ SG_ 1837 FRDistance268 "freespace点距离";
CM_ SG_ 1837 FRDistance269 "freespace点距离";
CM_ SG_ 1837 FRDistance270 "freespace点距离";
CM_ SG_ 1837 Counter_72D "计数校验";
CM_ SG_ 1838 FRDistance271 "freespace点距离";
CM_ SG_ 1838 FRDistance272 "freespace点距离";
CM_ SG_ 1838 FRDistance273 "freespace点距离";
CM_ SG_ 1838 FRDistance274 "freespace点距离";
CM_ SG_ 1838 FRDistance275 "freespace点距离";
CM_ SG_ 1838 FRDistance276 "freespace点距离";
CM_ SG_ 1838 Counter_72E "计数校验";
CM_ SG_ 1839 FRDistance277 "freespace点距离";
CM_ SG_ 1839 FRDistance278 "freespace点距离";
CM_ SG_ 1839 FRDistance279 "freespace点距离";
CM_ SG_ 1839 FRDistance280 "freespace点距离";
CM_ SG_ 1839 FRDistance281 "freespace点距离";
CM_ SG_ 1839 FRDistance282 "freespace点距离";
CM_ SG_ 1839 Counter_72F "计数校验";
CM_ SG_ 1840 FRDistance283 "freespace点距离";
CM_ SG_ 1840 FRDistance284 "freespace点距离";
CM_ SG_ 1840 FRDistance285 "freespace点距离";
CM_ SG_ 1840 FRDistance286 "freespace点距离";
CM_ SG_ 1840 FRDistance287 "freespace点距离";
CM_ SG_ 1840 FRDistance288 "freespace点距离";
CM_ SG_ 1840 Counter_730 "计数校验";
CM_ SG_ 1841 FRDistance289 "freespace点距离";
CM_ SG_ 1841 FRDistance290 "freespace点距离";
CM_ SG_ 1841 FRDistance291 "freespace点距离";
CM_ SG_ 1841 FRDistance292 "freespace点距离";
CM_ SG_ 1841 FRDistance293 "freespace点距离";
CM_ SG_ 1841 FRDistance294 "freespace点距离";
CM_ SG_ 1841 Counter_731 "计数校验";
CM_ SG_ 1842 FRDistance295 "freespace点距离";
CM_ SG_ 1842 FRDistance296 "freespace点距离";
CM_ SG_ 1842 FRDistance297 "freespace点距离";
CM_ SG_ 1842 FRDistance298 "freespace点距离";
CM_ SG_ 1842 FRDistance299 "freespace点距离";
CM_ SG_ 1842 FRDistance300 "freespace点距离";
CM_ SG_ 1842 Counter_732 "计数校验";
CM_ SG_ 1843 FRDistance301 "freespace点距离";
CM_ SG_ 1843 FRDistance302 "freespace点距离";
CM_ SG_ 1843 FRDistance303 "freespace点距离";
CM_ SG_ 1843 FRDistance304 "freespace点距离";
CM_ SG_ 1843 FRDistance305 "freespace点距离";
CM_ SG_ 1843 FRDistance306 "freespace点距离";
CM_ SG_ 1843 Counter_733 "计数校验";
CM_ SG_ 1844 FRDistance307 "freespace点距离";
CM_ SG_ 1844 FRDistance308 "freespace点距离";
CM_ SG_ 1844 FRDistance309 "freespace点距离";
CM_ SG_ 1844 FRDistance310 "freespace点距离";
CM_ SG_ 1844 FRDistance311 "freespace点距离";
CM_ SG_ 1844 FRDistance312 "freespace点距离";
CM_ SG_ 1844 Counter_734 "计数校验";
CM_ SG_ 1845 FRDistance313 "freespace点距离";
CM_ SG_ 1845 FRDistance314 "freespace点距离";
CM_ SG_ 1845 FRDistance315 "freespace点距离";
CM_ SG_ 1845 FRDistance316 "freespace点距离";
CM_ SG_ 1845 FRDistance317 "freespace点距离";
CM_ SG_ 1845 FRDistance318 "freespace点距离";
CM_ SG_ 1845 Counter_735 "计数校验";
CM_ SG_ 1846 FRDistance319 "freespace点距离";
CM_ SG_ 1846 FRDistance320 "freespace点距离";
CM_ SG_ 1846 FRDistance321 "freespace点距离";
CM_ SG_ 1846 FRDistance322 "freespace点距离";
CM_ SG_ 1846 FRDistance323 "freespace点距离";
CM_ SG_ 1846 FRDistance324 "freespace点距离";
CM_ SG_ 1846 Counter_736 "计数校验";
CM_ SG_ 1847 FRDistance325 "freespace点距离";
CM_ SG_ 1847 FRDistance326 "freespace点距离";
CM_ SG_ 1847 FRDistance327 "freespace点距离";
CM_ SG_ 1847 FRDistance328 "freespace点距离";
CM_ SG_ 1847 FRDistance329 "freespace点距离";
CM_ SG_ 1847 FRDistance330 "freespace点距离";
CM_ SG_ 1847 Counter_737 "计数校验";
CM_ SG_ 1848 FRDistance331 "freespace点距离";
CM_ SG_ 1848 FRDistance332 "freespace点距离";
CM_ SG_ 1848 FRDistance333 "freespace点距离";
CM_ SG_ 1848 FRDistance334 "freespace点距离";
CM_ SG_ 1848 FRDistance335 "freespace点距离";
CM_ SG_ 1848 FRDistance336 "freespace点距离";
CM_ SG_ 1848 Counter_738 "计数校验";
CM_ SG_ 1849 FRDistance337 "freespace点距离";
CM_ SG_ 1849 FRDistance338 "freespace点距离";
CM_ SG_ 1849 FRDistance339 "freespace点距离";
CM_ SG_ 1849 FRDistance340 "freespace点距离";
CM_ SG_ 1849 FRDistance341 "freespace点距离";
CM_ SG_ 1849 FRDistance342 "freespace点距离";
CM_ SG_ 1849 Counter_739 "计数校验";
CM_ SG_ 1850 FRDistance343 "freespace点距离";
CM_ SG_ 1850 FRDistance344 "freespace点距离";
CM_ SG_ 1850 FRDistance345 "freespace点距离";
CM_ SG_ 1850 FRDistance346 "freespace点距离";
CM_ SG_ 1850 FRDistance347 "freespace点距离";
CM_ SG_ 1850 FRDistance348 "freespace点距离";
CM_ SG_ 1850 Counter_73A "计数校验";
CM_ SG_ 1851 FRDistance349 "freespace点距离";
CM_ SG_ 1851 FRDistance350 "freespace点距离";
CM_ SG_ 1851 FRDistance351 "freespace点距离";
CM_ SG_ 1851 FRDistance352 "freespace点距离";
CM_ SG_ 1851 FRDistance353 "freespace点距离";
CM_ SG_ 1851 FRDistance354 "freespace点距离";
CM_ SG_ 1851 Counter_73B "计数校验";
CM_ SG_ 1852 FRDistance355 "freespace点距离";
CM_ SG_ 1852 FRDistance356 "freespace点距离";
CM_ SG_ 1852 FRDistance357 "freespace点距离";
CM_ SG_ 1852 FRDistance358 "freespace点距离";
CM_ SG_ 1852 FRDistance359 "freespace点距离";
CM_ SG_ 1852 FRDistance360 "freespace点距离";
CM_ SG_ 1852 Counter_73C "计数校验";
BA_DEF_ BO_  "GenMsgSendType" ENUM  "Cycle","NoSendType","IfActive";
BA_DEF_ BO_  "GenMsgCycleTime" INT 0 0;
BA_DEF_ SG_  "GenSigSendType" ENUM  "Cycle","OnChange","OnWrite","IfActive","OnChangeWithRepetition","OnWriteWithRepetition","IfActiveWithRepetition";
BA_DEF_ SG_  "GenSigStartValue" INT 0 0;
BA_DEF_  "DBName" STRING ;
BA_DEF_ BU_  "NodeLayerModules" STRING ;
BA_DEF_ BU_  "NmNode" ENUM  "Not","Yes";
BA_DEF_  "NmBaseAddress" HEX 0 2047;
BA_DEF_  "NmMessageCount" INT 0 255;
BA_DEF_  "BusType" STRING ;
BA_DEF_DEF_  "GenMsgSendType" "Cycle";
BA_DEF_DEF_  "GenMsgCycleTime" 0;
BA_DEF_DEF_  "GenSigSendType" "Cycle";
BA_DEF_DEF_  "GenSigStartValue" 0;
BA_DEF_DEF_  "DBName" "";
BA_DEF_DEF_  "NodeLayerModules" "oseknm01.dll,osek_tp.dll,CANoeILNLVector.dll";
BA_DEF_DEF_  "NmNode" "Not";
BA_DEF_DEF_  "NmBaseAddress" 1024;
BA_DEF_DEF_  "NmMessageCount" 128;
BA_DEF_DEF_  "BusType" "CAN";
BA_ "DBName" "LidarFreeSpace";
BA_ "GenMsgCycleTime" BO_ 1793 100;
BA_ "GenMsgCycleTime" BO_ 1794 100;
BA_ "GenMsgCycleTime" BO_ 1795 100;
BA_ "GenMsgCycleTime" BO_ 1796 100;
BA_ "GenMsgCycleTime" BO_ 1797 100;
BA_ "GenMsgCycleTime" BO_ 1798 100;
BA_ "GenMsgCycleTime" BO_ 1799 100;
BA_ "GenMsgCycleTime" BO_ 1800 100;
BA_ "GenMsgCycleTime" BO_ 1801 100;
BA_ "GenMsgCycleTime" BO_ 1802 100;
BA_ "GenMsgCycleTime" BO_ 1803 100;
BA_ "GenMsgCycleTime" BO_ 1804 100;
BA_ "GenMsgCycleTime" BO_ 1805 100;
BA_ "GenMsgCycleTime" BO_ 1806 100;
BA_ "GenMsgCycleTime" BO_ 1807 100;
BA_ "GenMsgCycleTime" BO_ 1808 100;
BA_ "GenMsgCycleTime" BO_ 1809 100;
BA_ "GenMsgCycleTime" BO_ 1810 100;
BA_ "GenMsgCycleTime" BO_ 1811 100;
BA_ "GenMsgCycleTime" BO_ 1812 100;
BA_ "GenMsgCycleTime" BO_ 1813 100;
BA_ "GenMsgCycleTime" BO_ 1814 100;
BA_ "GenMsgCycleTime" BO_ 1815 100;
BA_ "GenMsgCycleTime" BO_ 1816 100;
BA_ "GenMsgCycleTime" BO_ 1817 100;
BA_ "GenMsgCycleTime" BO_ 1818 100;
BA_ "GenMsgCycleTime" BO_ 1819 100;
BA_ "GenMsgCycleTime" BO_ 1820 100;
BA_ "GenMsgCycleTime" BO_ 1821 100;
BA_ "GenMsgCycleTime" BO_ 1822 100;
BA_ "GenMsgCycleTime" BO_ 1823 100;
BA_ "GenMsgCycleTime" BO_ 1824 100;
BA_ "GenMsgCycleTime" BO_ 1825 100;
BA_ "GenMsgCycleTime" BO_ 1826 100;
BA_ "GenMsgCycleTime" BO_ 1827 100;
BA_ "GenMsgCycleTime" BO_ 1828 100;
BA_ "GenMsgCycleTime" BO_ 1829 100;
BA_ "GenMsgCycleTime" BO_ 1830 100;
BA_ "GenMsgCycleTime" BO_ 1831 100;
BA_ "GenMsgCycleTime" BO_ 1832 100;
BA_ "GenMsgCycleTime" BO_ 1833 100;
BA_ "GenMsgCycleTime" BO_ 1834 100;
BA_ "GenMsgCycleTime" BO_ 1835 100;
BA_ "GenMsgCycleTime" BO_ 1836 100;
BA_ "GenMsgCycleTime" BO_ 1837 100;
BA_ "GenMsgCycleTime" BO_ 1838 100;
BA_ "GenMsgCycleTime" BO_ 1839 100;
BA_ "GenMsgCycleTime" BO_ 1840 100;
BA_ "GenMsgCycleTime" BO_ 1841 100;
BA_ "GenMsgCycleTime" BO_ 1842 100;
BA_ "GenMsgCycleTime" BO_ 1843 100;
BA_ "GenMsgCycleTime" BO_ 1844 100;
BA_ "GenMsgCycleTime" BO_ 1845 100;
BA_ "GenMsgCycleTime" BO_ 1846 100;
BA_ "GenMsgCycleTime" BO_ 1847 100;
BA_ "GenMsgCycleTime" BO_ 1848 100;
BA_ "GenMsgCycleTime" BO_ 1849 100;
BA_ "GenMsgCycleTime" BO_ 1850 100;
BA_ "GenMsgCycleTime" BO_ 1851 100;
BA_ "GenMsgCycleTime" BO_ 1852 100;
BA_ "GenSigStartValue" SG_ 3221225472 IPC_BayRemainingDistanceX 3000;
BA_ "GenSigStartValue" SG_ 3221225472 IPC_BayRemainingDistanceY 3000;
VAL_ 3221225472 GPS_flag_pos 3 "纯惯" 2 "组合" 1 "姿态初始化" 0 "无" ;
VAL_ 3221225472 GPS_age 50 "Narrow_Int" 34 "Narrow_Float" 17 "Psrdiff" 16 "Single" 0 "None" ;
VAL_ 3221225472 GPS_numsv 50 "Narrow_Int" 34 "Narrow_Float" 17 "Psrdiff" 16 "Single" 0 "None" ;
VAL_ 3221225472 IPC_CPSLaneNumber 15 "Black" 14 "Reserved" 13 "Reserved" 12 "Reserved" 11 "Reserved" 10 "Reserved" 9 "Reserved" 8 "Reserved" 7 "Lane7" 6 "Lane6" 5 "Lane5" 4 "Lane4" 3 "Lane3" 2 "Lane2" 1 "Lane1" 0 "Invalid" ;
VAL_ 3221225472 IPC_CPSDirectionIndication 3 "Reserved" 2 "Backward" 1 "Forward" 0 "Invalid" ;
VAL_ 3221225472 IPC_CPSCameraUsed 3 "Reserved" 2 "Right" 1 "Left" 0 "Invalid" ;
VAL_ 3221225472 IPC_BayNumberCameraUsed 3 "Reserved" 2 "Right" 1 "Left" 0 "Invalid" ;
VAL_ 3221225472 IPC_BayNumber 255 "Invalid" 254 "Black" ;
VAL_ 3221225472 IPC_BayRemainingDistanceX 65535 "Invalid" ;
VAL_ 3221225472 IPC_BayRemainingDistanceY 65535 "Invalid" ;
VAL_ 3221225472 IPC_CPSDisplayNumber 255 "Invalid" 254 "Black" 253 "Parking in place" ;
VAL_ 3221225472 IPC_ContainerSizeAndPosition 15 "Invalid" 14 "Reserved" 13 "Reserved" 12 "Reserved" 11 "Reserved" 10 "Reserved" 9 "Reserved" 8 "Reserved" 7 "Reserved" 6 "Reserved" 5 "Reserved" 4 "Small Double Front and Rear" 3 "Small Single Rear" 2 "Small Single Front" 1 "Large Single" 0 "NO Container" ;
VAL_ 3221225472 IPC_CPSRightCameraStatus 31 "Invalid" 30 "Reserved" 29 "Reserved" 28 "Reserved" 27 "Reserved" 26 "Reserved" 25 "Reserved" 24 "Reserved" 23 "Reserved" 22 "Reserved" 21 "Reserved" 20 "Reserved" 19 "Reserved" 18 "Reserved" 17 "Reserved" 16 "Reserved" 15 "Reserved" 14 "Reserved" 13 "Reserved" 12 "Reserved" 11 "Reserved" 10 "Reserved" 9 "Reserved" 8 "Reserved" 7 "Reserved" 6 "Reserved" 5 "Unknown Reason" 4 "Poor Image Quality" 3 "Askew" 2 "Blocked" 1 "No Signal" 0 "N0 Fault" ;
VAL_ 3221225472 IPC_BayNumLeftCameraStatus 31 "Invalid" 30 "Reserved" 29 "Reserved" 28 "Reserved" 27 "Reserved" 26 "Reserved" 25 "Reserved" 24 "Reserved" 23 "Reserved" 22 "Reserved" 21 "Reserved" 20 "Reserved" 19 "Reserved" 18 "Reserved" 17 "Reserved" 16 "Reserved" 15 "Reserved" 14 "Reserved" 13 "Reserved" 12 "Reserved" 11 "Reserved" 10 "Reserved" 9 "Reserved" 8 "Reserved" 7 "Reserved" 6 "Reserved" 5 "Unknown Reason" 4 "Poor Image Quality" 3 "Askew" 2 "Blocked" 1 "No Signal" 0 "N0 Fault" ;
VAL_ 3221225472 IPC_BayNumRightCameraStatus 31 "Invalid" 30 "Reserved" 29 "Reserved" 28 "Reserved" 27 "Reserved" 26 "Reserved" 25 "Reserved" 24 "Reserved" 23 "Reserved" 22 "Reserved" 21 "Reserved" 20 "Reserved" 19 "Reserved" 18 "Reserved" 17 "Reserved" 16 "Reserved" 15 "Reserved" 14 "Reserved" 13 "Reserved" 12 "Reserved" 11 "Reserved" 10 "Reserved" 9 "Reserved" 8 "Reserved" 7 "Reserved" 6 "Reserved" 5 "Unknown Reason" 4 "Poor Image Quality" 3 "Askew" 2 "Blocked" 1 "No Signal" 0 "N0 Fault" ;
VAL_ 3221225472 IPC_HangerCameraStatus 31 "Invalid" 30 "Reserved" 29 "Reserved" 28 "Reserved" 27 "Reserved" 26 "Reserved" 25 "Reserved" 24 "Reserved" 23 "Reserved" 22 "Reserved" 21 "Reserved" 20 "Reserved" 19 "Reserved" 18 "Reserved" 17 "Reserved" 16 "Reserved" 15 "Reserved" 14 "Reserved" 13 "Reserved" 12 "Reserved" 11 "Reserved" 10 "Reserved" 9 "Reserved" 8 "Reserved" 7 "Reserved" 6 "Reserved" 5 "Unknown Reason" 4 "Poor Image Quality" 3 "Askew" 2 "Blocked" 1 "No Signal" 0 "N0 Fault" ;
VAL_ 3221225472 IPC_HangerStatus 15 "Invalid" 14 "Reserved" 13 "Reserved" 12 "Reserved" 11 "Reserved" 10 "Reserved" 9 "Reserved" 8 "Reserved" 7 "Reserved" 6 "Reserved" 5 "Reserved" 4 "Reserved" 3 "Small Single Rear" 2 "Small Single Front" 1 "Large Single" 0 "None" ;
VAL_ 3221225472 IPC_CPSLeftCameraStatus 31 "Invalid" 30 "Reserved" 29 "Reserved" 28 "Reserved" 27 "Reserved" 26 "Reserved" 25 "Reserved" 24 "Reserved" 23 "Reserved" 22 "Reserved" 21 "Reserved" 20 "Reserved" 19 "Reserved" 18 "Reserved" 17 "Reserved" 16 "Reserved" 15 "Reserved" 14 "Reserved" 13 "Reserved" 12 "Reserved" 11 "Reserved" 10 "Reserved" 9 "Reserved" 8 "Reserved" 7 "Reserved" 6 "Reserved" 5 "Unknown Reason" 4 "Poor Image Quality" 3 "Askew" 2 "Blocked" 1 "No Signal" 0 "N0 Fault" ;
